AUTOSAR XML (schema 4-3-0)
standard types defined: sint8, sint16, sint32, sint64, uint8, uint16, uint32, uint64, float32, float64, boolean
package /MQBw_Baseline
  system System
    system mapping System_Mappings
      data-mappings:
        communication-direction=IN, data-element=Grundumfang_XIX_eCS.Geltungsbereich_MQBw_Baseline.RP_IF_AB_Crash_Int_XIX_Grundumfang_XIX_eCS.DE_AB_Crash_Int, system-signal=AB_Crash_Int
        communication-direction=IN, data-element=Grundumfang_XIX_eCS.Geltungsbereich_MQBw_Baseline.RP_IF_AB_Gurtschloss_Reihe2_BF_XIX_Grundumfang_XIX_eCS.DE_AB_Gurtschloss_Reihe2_BF, system-signal=AB_Gurtschloss_Reihe2_BF
        communication-direction=IN, data-element=Grundumfang_XIX_eCS.Geltungsbereich_MQBw_Baseline.RP_IF_AB_Gurtschloss_BF_XIX_Grundumfang_XIX_eCS.DE_AB_Gurtschloss_BF, system-signal=AB_Gurtschloss_BF
        communication-direction=IN, data-element=Grundumfang_XIX_eCS.Geltungsbereich_MQBw_Baseline.RP_IF_AB_Gurtschloss_Reihe2_FA_XIX_Grundumfang_XIX_eCS.DE_AB_Gurtschloss_Reihe2_FA, system-signal=AB_Gurtschloss_Reihe2_FA
        communication-direction=IN, data-element=Grundumfang_XIX_eCS.Geltungsbereich_MQBw_Baseline.RP_IF_AB_Gurtschloss_Reihe3_BF_XIX_Grundumfang_XIX_eCS.DE_AB_Gurtschloss_Reihe3_BF, system-signal=AB_Gurtschloss_Reihe3_BF
        communication-direction=IN, data-element=Grundumfang_XIX_eCS.Geltungsbereich_MQBw_Baseline.RP_IF_AB_Gurtschloss_Reihe3_FA_XIX_Grundumfang_XIX_eCS.DE_AB_Gurtschloss_Reihe3_FA, system-signal=AB_Gurtschloss_Reihe3_FA
        communication-direction=IN, data-element=Grundumfang_XIX_eCS.Geltungsbereich_MQBw_Baseline.RP_IF_AB_Gurtschloss_FA_XIX_Grundumfang_XIX_eCS.DE_AB_Gurtschloss_FA, system-signal=AB_Gurtschloss_FA
        communication-direction=OUT, data-element=Grundumfang_XIX_eCS.Geltungsbereich_MQBw_Baseline.SP_IF_eCS_HW_defekt_XIX_Grundumfang_XIX_eCS.DE_eCS_HW_defekt, system-signal=eCS_HW_defekt
        communication-direction=OUT, data-element=Grundumfang_XIX_eCS.Geltungsbereich_MQBw_Baseline.SP_IF_eCS_Gurtschloss_Status_Reihe2_FA_XIX_Grundumfang_XIX_eCS.DE_eCS_Gurtschloss_Status_Reihe2_FA, system-signal=eCS_Gurtschloss_Status_Reihe2_FA
        communication-direction=OUT, data-element=Grundumfang_XIX_eCS.Geltungsbereich_MQBw_Baseline.SP_IF_eCS_SBS_Belegung_Reihe2_BF_XIX_Grundumfang_XIX_eCS.DE_eCS_SBS_Belegung_Reihe2_BF, system-signal=eCS_SBS_Belegung_Reihe2_BF
        communication-direction=OUT, data-element=Grundumfang_XIX_eCS.Geltungsbereich_MQBw_Baseline.SP_IF_eCS_Status_XIX_Grundumfang_XIX_eCS.DE_eCS_Status, system-signal=eCS_Status
        communication-direction=OUT, data-element=Grundumfang_XIX_eCS.Geltungsbereich_MQBw_Baseline.SP_IF_eCS_Gurtschloss_Status_Reihe2_BF_XIX_Grundumfang_XIX_eCS.DE_eCS_Gurtschloss_Status_Reihe2_BF, system-signal=eCS_Gurtschloss_Status_Reihe2_BF
        communication-direction=OUT, data-element=Grundumfang_XIX_eCS.Geltungsbereich_MQBw_Baseline.SP_IF_eCS_SBS_Belegung_Reihe2_FA_XIX_Grundumfang_XIX_eCS.DE_eCS_SBS_Belegung_Reihe2_FA, system-signal=eCS_SBS_Belegung_Reihe2_FA
        communication-direction=OUT, data-element=Grundumfang_XIX_eCS.Geltungsbereich_MQBw_Baseline.SP_IF_eCS_Stoerung_XIX_Grundumfang_XIX_eCS.DE_eCS_Stoerung, system-signal=eCS_Stoerung
        communication-direction=IN, data-element=Grundumfang_XIX_eCS.Geltungsbereich_MQBw_Baseline.RP_IF_AB_eCS_Aktuatortest_FA_XIX_Grundumfang_XIX_eCS.DE_AB_eCS_Aktuatortest_FA, system-signal=AB_eCS_Aktuatortest_FA
        communication-direction=IN, data-element=Grundumfang_XIX_eCS.Geltungsbereich_MQBw_Baseline.RP_IF_AB_eCS_Aktuatortest_Reihe2_BF_XIX_Grundumfang_XIX_eCS.DE_AB_eCS_Aktuatortest_Reihe2_BF, system-signal=AB_eCS_Aktuatortest_Reihe2_BF
        communication-direction=IN, data-element=Grundumfang_XIX_eCS.Geltungsbereich_MQBw_Baseline.RP_IF_AB_eCS_Aktuatortest_BF_XIX_Grundumfang_XIX_eCS.DE_AB_eCS_Aktuatortest_BF, system-signal=AB_eCS_Aktuatortest_BF
        communication-direction=IN, data-element=Grundumfang_XIX_eCS.Geltungsbereich_MQBw_Baseline.RP_IF_AB_eCS_Aktuatortest_Reihe3_BF_XIX_Grundumfang_XIX_eCS.DE_AB_eCS_Aktuatortest_Reihe3_BF, system-signal=AB_eCS_Aktuatortest_Reihe3_BF
        communication-direction=IN, data-element=Grundumfang_XIX_eCS.Geltungsbereich_MQBw_Baseline.RP_IF_AB_eCS_Aktuatortest_Reihe3_FA_XIX_Grundumfang_XIX_eCS.DE_AB_eCS_Aktuatortest_Reihe3_FA, system-signal=AB_eCS_Aktuatortest_Reihe3_FA
        communication-direction=IN, data-element=Grundumfang_XIX_eCS.Geltungsbereich_MQBw_Baseline.RP_IF_AB_eCS_Aktuatortest_Reihe2_FA_XIX_Grundumfang_XIX_eCS.DE_AB_eCS_Aktuatortest_Reihe2_FA, system-signal=AB_eCS_Aktuatortest_Reihe2_FA
      sw-mappings:
        swc to ecu mapping MAPPING_Grundumfang_XIX_eCS: component=Geltungsbereich_MQBw_Baseline.Grundumfang_XIX_eCS, ecu-instance=eCS
    root-software-compositions:
      root sw composition prototype Geltungsbereich_MQBw_Baseline: software-composition=Geltungsbereich_MQBw_Baseline
package /ECU
  ecu instance eCS: associated-com-i-pdu-group=[eCS_XIX_Airbag_SUBCANFD_Tx, eCS_XIX_Airbag_SUBCANFD_Rx], diagnostic-address=16902, sleep-mode-supported=true, wake-up-over-bus-supported=false
    can communication controller CT_Airbag_SUBCANFD: wake-up-by-controller-supported=true, can-controller-attributes=can-controller-configuration-requirements={can-controller-fd-requirements={max-number-of-time-quanta-per-bit=20, max-sample-point=80.0, max-sync-jump-width=20.0, min-number-of-time-quanta-per-bit=20, min-sample-point=80.0, min-sync-jump-width=20.0}, max-number-of-time-quanta-per-bit=20, max-sample-point=80.0, max-sync-jump-width=20.0, min-number-of-time-quanta-per-bit=20, min-sample-point=80.0, min-sync-jump-width=20.0}
    can communication connector CN_Airbag_SUBCANFD: comm-controller=CT_Airbag_SUBCANFD, pnc-gateway-type=NONE
package /Cluster
  can cluster Airbag_SUBCANFD: baudrate=500000, protocol-name=CAN, protocol-version=2.0, bus-off-recovery={bor-counter-l-1-to-l-2=1, bor-time-l-1=0.05, bor-time-l-2=0.2}, can-fd-baudrate=500000  # SubCAN FD Airbag
    can physical channel CHNL: comm-connectors=CN_Airbag_SUBCANFD
      frame Airbag_01_XIX_Airbag_SUBCANFD: id 0x40, to eCS, frame-length=8, can-addressing-mode=STANDARD, can-frame-rx-behavior=CAN-FD, can-frame-tx-behavior=CAN-FD
        pdu Airbag_01_XIX_Airbag_SUBCANFD: length=8, minimum-delay=0.01, transmission-mode-true-timing={cyclic-timing={time-offset=0, time-period=0.04}, event-controlled-timing={number-of-repetitions=5, repetition-period=0.01}}, unused-bit-pattern=0
          signal Airbag_01_CRC_XIX_Airbag_01_XIX_Airbag_SUBCANFD: start 0, 8 bit, little-endian, data-type-policy=OVERRIDE, i-signal-type=PRIMITIVE, base-type=BT_Airbag_01_CRC, compu {phys=raw for raw 0..255}, range phys 0..255, raw 0..255, transfer-property=TRIGGERED-WITHOUT-REPETITION  # Für MLB: "Berechnung siehe Lastenheft "Kommunikationsabsicherung für FlexRay und CAN"" Ab MQB und MLBevo: "Berechnung siehe Lastenheft "End-to-End Kommunikationsabsicherung"" Endwerte siehe Begleitdokument "S-PDU Kennungsfolgen"
          signal Airbag_01_BZ_XIX_Airbag_01_XIX_Airbag_SUBCANFD: start 8, 4 bit, little-endian, data-type-policy=OVERRIDE, i-signal-type=PRIMITIVE, base-type=BT_Airbag_01_BZ, compu {phys=raw for raw 0..15}, range phys 0..15, raw 0..15, transfer-property=TRIGGERED-WITHOUT-REPETITION
          signal AB_RGS_Anst_XIX_Airbag_01_XIX_Airbag_SUBCANFD: start 12, 4 bit, little-endian, data-type-policy=OVERRIDE, i-signal-type=PRIMITIVE, init-value=8, base-type=BT_AB_RGS_Anst, compu {4=Cx4_aktiv_Niveau_1 (CM_AB_RGS_Anst_Cx4_aktiv_Niveau_1), 5=Cx5_aktiv_Niveau_2 (CM_AB_RGS_Anst_Cx5_aktiv_Niveau_2), 8=Cx8_deaktiviert (CM_AB_RGS_Anst_Cx8_deaktiviert), 6=Cx6_aktiv_Niveau_3 (CM_AB_RGS_Anst_Cx6_aktiv_Niveau_3), 7=Cx7_aktiv_Niveau_4 (CM_AB_RGS_Anst_Cx7_aktiv_Niveau_4)}, range raw 4..8, transfer-property=TRIGGERED-WITHOUT-REPETITION  # PreCrash-Ansteuerung reversibler Gurtstraffer (Aktivierung und Kraftniveau) 10xx = deaktiviert
          signal AB_Front_Crash_XIX_Airbag_01_XIX_Airbag_SUBCANFD: start 16, 1 bit, little-endian, data-type-policy=OVERRIDE, i-signal-type=PRIMITIVE, init-value=0, base-type=BT_AB_Front_Crash, compu {1=Cx1_Front_Crash (CM_AB_Front_Crash_Cx1_Front_Crash), 0=Cx0_kein_Front_Crash (CM_AB_Front_Crash_Cx0_kein_Front_Crash)}, range raw 0..1, transfer-property=TRIGGERED-WITHOUT-REPETITION  # Bit wird bei Überschreitung der Gurtstraffer-, US- und RdW-Schwelle gesetzt
          signal AB_Heck_Crash_XIX_Airbag_01_XIX_Airbag_SUBCANFD: start 17, 1 bit, little-endian, data-type-policy=OVERRIDE, i-signal-type=PRIMITIVE, init-value=0, base-type=BT_AB_Heck_Crash, compu {1=Cx1_Heck_Crash (CM_AB_Heck_Crash_Cx1_Heck_Crash), 0=Cx0_kein_Heck_Crash (CM_AB_Heck_Crash_Cx0_kein_Heck_Crash)}, range raw 0..1, transfer-property=TRIGGERED-WITHOUT-REPETITION  # Wird für alle neu anlaufenden Projekte umgesetzt: AB8.4, Audi8/VW8
          signal AB_SF_Crash_XIX_Airbag_01_XIX_Airbag_SUBCANFD: start 18, 1 bit, little-endian, data-type-policy=OVERRIDE, i-signal-type=PRIMITIVE, init-value=0, base-type=BT_AB_SF_Crash, compu {0=Cx0_kein_Seiten_Crash_Fahrer (CM_AB_SF_Crash_Cx0_kein_Seiten_Crash_Fahrer), 1=Cx1_Seiten_Crash_Fahrer (CM_AB_SF_Crash_Cx1_Seiten_Crash_Fahrer)}, range raw 0..1, transfer-property=TRIGGERED-WITHOUT-REPETITION  # Z.Zt. nur in Verbindung mit Crash-Intensität >= 100b (Kraftstoffpumpenabschaltung) verwendet.
          signal AB_SB_Crash_XIX_Airbag_01_XIX_Airbag_SUBCANFD: start 19, 1 bit, little-endian, data-type-policy=OVERRIDE, i-signal-type=PRIMITIVE, init-value=0, base-type=BT_AB_SB_Crash, compu {0=Cx0_kein_Seiten_Crash_Beifahrer (CM_AB_SB_Crash_Cx0_kein_Seiten_Crash_Beifahrer), 1=Cx1_Seiten_Crash_Beifahrer (CM_AB_SB_Crash_Cx1_Seiten_Crash_Beifahrer)}, range raw 0..1, transfer-property=TRIGGERED-WITHOUT-REPETITION  # Z.Zt. nur in Verbindung mit Crash-Intensität >= 100b (Kraftstoffpumpenabschaltung) verwendet.
          signal AB_Rollover_Crash_XIX_Airbag_01_XIX_Airbag_SUBCANFD: start 20, 1 bit, little-endian, data-type-policy=OVERRIDE, i-signal-type=PRIMITIVE, init-value=0, base-type=BT_AB_Rollover_Crash, compu {0=Cx0_kein_Rollover (CM_AB_Rollover_Crash_Cx0_kein_Rollover), 1=Cx1_Rollover (CM_AB_Rollover_Crash_Cx1_Rollover)}, range raw 0..1, transfer-property=TRIGGERED-WITHOUT-REPETITION  # Wird im B6/B7 Cabrio und New Beetle Cabrio bedient.
          signal AB_Crash_Int_XIX_Airbag_01_XIX_Airbag_SUBCANFD: start 21, 3 bit, little-endian, data-type-policy=OVERRIDE, i-signal-type=PRIMITIVE, init-value=0, base-type=BT_AB_Crash_Int, compu {3=Cx3_Crash_Intensitaet_2_nur_D4_C7_Colorado_NF_PAG_Crash_im_MLB_B8 (CM_AB_Crash_Int_Cx3_Crash_Intensitaet_2_nur_D4_C7_Colorado_NF_PAG_Crash_im_MLB_B8) (Crash_Intensitaet_2_(nur_D4_C7_Colorado_NF_PAG__Crash_im_MLB_B8)), 1=Cx1_Crash_Intensitaet_1 (CM_AB_Crash_Int_Cx1_Crash_Intensitaet_1), 5=Cx5_Crash_Intensitaet_3_alt_PAG (CM_AB_Crash_Int_Cx5_Crash_Intensitaet_3_alt_PAG) (Crash_Intensitaet_3_(alt_PAG)), 7=Cx7_Crash_Intensitaet_3 (CM_AB_Crash_Int_Cx7_Crash_Intensitaet_3), 0=Cx0_kein_Crash (CM_AB_Crash_Int_Cx0_kein_Crash), 2=Cx2_Crash_Intensitaet_2_nur_Stellgliedtest_MLB_B8 (CM_AB_Crash_Int_Cx2_Crash_Intensitaet_2_nur_Stellgliedtest_MLB_B8) (Crash_Intensitaet_2_(nur_Stellgliedtest_MLB_B8)), 4=Cx4_Crash_Intensitaet_3_alt_VW_AUDI_Stellgliedtest_MLB_B8 (CM_AB_Crash_Int_Cx4_Crash_Intensitaet_3_alt_VW_AUDI_Stellgliedtest_MLB_B8) (Crash_Intensitaet_3_(alt_VW/AUDI__Stellgliedtest_MLB_B8))}, range raw 0..7, transfer-property=TRIGGERED-WITHOUT-REPETITION, to eCS(timeout 0.5 s)  # Crash_Intensität_1 = fahrzeugabhängige Reaktionen im Crash Crash_Intensität_2 = fahrzeugabhängige Reaktionen im Crash Crash_Intensität_3 = fahrzeugabhängige Reaktionen im Crash Die jeweiligen fahrzeugabhängigen Reaktionen im Crash sind in einem separaten Doors Modul im Airbag-SG beschrieben. Die Information bleibt bei jeder Schwellwert-überschreitung für ~10 s bestehen (Achtung: Energiereserve bei abgetrennter Batterie reicht worstcase nur für 150 ms)
          signal AB_Lampe_XIX_Airbag_01_XIX_Airbag_SUBCANFD: start 24, 1 bit, little-endian, data-type-policy=OVERRIDE, i-signal-type=PRIMITIVE, init-value=1, base-type=BT_AB_Lampe, compu {0=Cx0_Aus (CM_AB_Lampe_Cx0_Aus), 1=Cx1_Ein (CM_AB_Lampe_Cx1_Ein)}, range raw 0..1, transfer-property=TRIGGERED-WITHOUT-REPETITION  # Sicherheitswarnlampe im Kombi wird vom Airbag-SG angesteuert; Zustand der Lampe wird auf dem CAN-Bus ausgegeben (auch Blinkinformation).
          signal AB_Deaktiviert_XIX_Airbag_01_XIX_Airbag_SUBCANFD: start 25, 1 bit, little-endian, data-type-policy=OVERRIDE, i-signal-type=PRIMITIVE, init-value=0, base-type=BT_AB_Deaktiviert, compu {0=Cx0_aktiv (CM_AB_Deaktiviert_Cx0_aktiv), 1=Cx1_deaktiviert (CM_AB_Deaktiviert_Cx1_deaktiviert)}, range raw 0..1, transfer-property=TRIGGERED-WITHOUT-REPETITION  # Airbag oder Gurtstraffer wurden per Anpassung deaktiviert: Aktualisierung erst nach Selbsttest
          signal AB_VB_deaktiviert_XIX_Airbag_01_XIX_Airbag_SUBCANFD: start 26, 1 bit, little-endian, data-type-policy=OVERRIDE, i-signal-type=PRIMITIVE, init-value=1, base-type=BT_AB_VB_deaktiviert, compu {1=Cx1_Beifahrerairbag_deaktiviert (CM_AB_VB_deaktiviert_Cx1_Beifahrerairbag_deaktiviert), 0=Cx0_Beifahrerairbag_aktiv (CM_AB_VB_deaktiviert_Cx0_Beifahrerairbag_aktiv)}, range raw 0..1, transfer-property=TRIGGERED-WITHOUT-REPETITION  # Als Option vorgehalten, Beifahrerairbag wurden per Schlüsselschalter oder Insassenerkennung deaktiviert
          signal AB_Systemfehler_XIX_Airbag_01_XIX_Airbag_SUBCANFD: start 27, 1 bit, little-endian, data-type-policy=OVERRIDE, i-signal-type=PRIMITIVE, init-value=0, base-type=BT_AB_Systemfehler, compu {0=Cx0_kein_Fehler (CM_AB_Systemfehler_Cx0_kein_Fehler), 1=Cx1_Airbag_Systemfehler (CM_AB_Systemfehler_Cx1_Airbag_Systemfehler)}, range raw 0..1, transfer-property=TRIGGERED-WITHOUT-REPETITION  # Systemfehler Ggf. wird Warnlampe dauernd eingeschaltet.
          signal AB_Diagnose_XIX_Airbag_01_XIX_Airbag_SUBCANFD: start 28, 1 bit, little-endian, data-type-policy=OVERRIDE, i-signal-type=PRIMITIVE, init-value=0, base-type=BT_AB_Diagnose, compu {1=Cx1_in_Diagnose (CM_AB_Diagnose_Cx1_in_Diagnose), 0=Cx0_nicht_in_Diagnose (CM_AB_Diagnose_Cx0_nicht_in_Diagnose)}, range raw 0..1, transfer-property=TRIGGERED-WITHOUT-REPETITION  # Airbag in Diagnose
          signal AB_Stellgliedtest_XIX_Airbag_01_XIX_Airbag_SUBCANFD: start 29, 1 bit, little-endian, data-type-policy=OVERRIDE, i-signal-type=PRIMITIVE, init-value=0, base-type=BT_AB_Stellgliedtest, compu {0=Cx0_nicht_im_Stellgliedtest (CM_AB_Stellgliedtest_Cx0_nicht_im_Stellgliedtest), 1=Cx1_Airbag_im_Stellgliedtest (CM_AB_Stellgliedtest_Cx1_Airbag_im_Stellgliedtest)}, range raw 0..1, transfer-property=TRIGGERED-WITHOUT-REPETITION  # Information, ob Airbag im Stellgliedtest ist, um eine Notrufauflösung beim Stellgliedtest zu verhindern
          signal AB_Erh_Auf_VB_XIX_Airbag_01_XIX_Airbag_SUBCANFD: start 30, 2 bit, little-endian, data-type-policy=OVERRIDE, i-signal-type=PRIMITIVE, init-value=0, base-type=BT_AB_Erh_Auf_VB, compu {2=Cx2_Beifahrerairbag_aktiviert (CM_AB_Erh_Auf_VB_Cx2_Beifahrerairbag_aktiviert), 1=Cx1_Beifahrerairbag_deaktiviert (CM_AB_Erh_Auf_VB_Cx1_Beifahrerairbag_deaktiviert), 3=Cx3_nicht_definiert (CM_AB_Erh_Auf_VB_Cx3_nicht_definiert), 0=Cx0_keine_Anzeige (CM_AB_Erh_Auf_VB_Cx0_keine_Anzeige)}, range raw 0..3, transfer-property=TRIGGERED-WITHOUT-REPETITION  # Der Fahrer soll bei einem Statuswechsel des Beifahrerairbags (ausgelöst durch die Beifahrerinsassenerkennung oder den Schlüsselschloßschalter) aufmerksam gemacht werden durch eine Anzeige im Kombi. Nur Audi: gültig für: AB2 (4-Türer AU352), B7, C6, D3
          signal AB_Gurtwarn_VF_XIX_Airbag_01_XIX_Airbag_SUBCANFD: start 32, 1 bit, little-endian, data-type-policy=OVERRIDE, i-signal-type=PRIMITIVE, init-value=0, base-type=BT_AB_Gurtwarn_VF, compu {1=Cx1_Gurtwarnung_ausloesen (CM_AB_Gurtwarn_VF_Cx1_Gurtwarnung_ausloesen), 0=Cx0_keine_Warnung (CM_AB_Gurtwarn_VF_Cx0_keine_Warnung)}, range raw 0..1, transfer-property=TRIGGERED-WITHOUT-REPETITION  # Fahrer hat Gurt nicht gesteckt, Anzeige im Kombi
          signal AB_Gurtwarn_VB_XIX_Airbag_01_XIX_Airbag_SUBCANFD: start 33, 1 bit, little-endian, data-type-policy=OVERRIDE, i-signal-type=PRIMITIVE, init-value=0, base-type=BT_AB_Gurtwarn_VB, compu {1=Cx1_Gurtwarnung_ausloesen (CM_AB_Gurtwarn_VB_Cx1_Gurtwarnung_ausloesen), 0=Cx0_keine_Warnung (CM_AB_Gurtwarn_VB_Cx0_keine_Warnung)}, range raw 0..1, transfer-property=TRIGGERED-WITHOUT-REPETITION  # Beifahrer hat Gurt nicht gesteckt, Anzeige im Kombi
          signal AB_Anzeige_Fussg_XIX_Airbag_01_XIX_Airbag_SUBCANFD: start 34, 2 bit, little-endian, data-type-policy=OVERRIDE, i-signal-type=PRIMITIVE, init-value=0, base-type=BT_AB_Anzeige_Fussg, compu {0=Cx0_keine_FSG_Aktion_ausgeloest (CM_AB_Anzeige_Fussg_Cx0_keine_FSG_Aktion_ausgeloest), 1=Cx1_Motorhaube_offen (CM_AB_Anzeige_Fussg_Cx1_Motorhaube_offen), 2=Cx2_Systemfehler (CM_AB_Anzeige_Fussg_Cx2_Systemfehler)}, range raw 0..2, transfer-property=TRIGGERED-WITHOUT-REPETITION  # Anzeige für ausgelöste Fussgängerschutz-Aktuatorik
          signal AB_Texte_AKS_XIX_Airbag_01_XIX_Airbag_SUBCANFD: start 36, 2 bit, little-endian, data-type-policy=OVERRIDE, i-signal-type=PRIMITIVE, init-value=0, base-type=BT_AB_Texte_AKS, compu {0=Cx0_keine_AKS_Ausloesung (CM_AB_Texte_AKS_Cx0_keine_AKS_Ausloesung), 1=Cx1_AKS_ausgeloest (CM_AB_Texte_AKS_Cx1_AKS_ausgeloest), 2=Cx2_AKS_Systemfehler (CM_AB_Texte_AKS_Cx2_AKS_Systemfehler)}, range raw 0..2, transfer-property=TRIGGERED-WITHOUT-REPETITION  # Textanzeige für pyrotechnische Auslösung der aktiven Kopfstütze (AKS)
          signal AB_PAO_Leuchte_Anf_XIX_Airbag_01_XIX_Airbag_SUBCANFD: start 38, 1 bit, little-endian, data-type-policy=OVERRIDE, i-signal-type=PRIMITIVE, init-value=1, base-type=BT_AB_PAO_Leuchte_Anf, compu {0=Cx0_Leuchte_ausschalten (CM_AB_PAO_Leuchte_Anf_Cx0_Leuchte_ausschalten), 1=Cx1_Leuchte_einschalten (CM_AB_PAO_Leuchte_Anf_Cx1_Leuchte_einschalten)}, range raw 0..1, transfer-property=TRIGGERED-WITHOUT-REPETITION  # Anforderung an die Passenger-Airbag-Off Leuchte in der Dachkonsole (ein / aus), Einsatz nur bei PAG
          signal AB_MKB_gueltig_XIX_Airbag_01_XIX_Airbag_SUBCANFD: start 39, 1 bit, little-endian, data-type-policy=OVERRIDE, i-signal-type=PRIMITIVE, init-value=0, base-type=BT_AB_MKB_gueltig, compu {0=Cx0_Multikollisionsbremsung_nicht_freigeschaltet (CM_AB_MKB_gueltig_Cx0_Multikollisionsbremsung_nicht_freigeschaltet), 1=Cx1_Multikollisionsbremsung_freigeschaltet (CM_AB_MKB_gueltig_Cx1_Multikollisionsbremsung_freigeschaltet)}, range raw 0..1, transfer-property=TRIGGERED-WITHOUT-REPETITION  # Multi-Kollisions-Bremsung im Airbag freigeschaltet
          signal AB_MKB_Anforderung_XIX_Airbag_01_XIX_Airbag_SUBCANFD: start 40, 1 bit, little-endian, data-type-policy=OVERRIDE, i-signal-type=PRIMITIVE, init-value=0, base-type=BT_AB_MKB_Anforderung, compu {0=Cx0_Multikollisionsbremsung_nicht_angefordert (CM_AB_MKB_Anforderung_Cx0_Multikollisionsbremsung_nicht_angefordert), 1=Cx1_Multikollisionsbremsung_angefordert (CM_AB_MKB_Anforderung_Cx1_Multikollisionsbremsung_angefordert)}, range raw 0..1, transfer-property=TRIGGERED-WITHOUT-REPETITION  # Anforderung Multi-Kollisions-Bremsung
          signal AB_Versorgungsspannung_XIX_Airbag_01_XIX_Airbag_SUBCANFD: start 41, 1 bit, little-endian, data-type-policy=OVERRIDE, i-signal-type=PRIMITIVE, init-value=0, base-type=BT_AB_Versorgungsspannung, compu {0=Cx0_plausibel (CM_AB_Versorgungsspannung_Cx0_plausibel), 1=Cx1_unplausibel (CM_AB_Versorgungsspannung_Cx1_unplausibel)}, range raw 0..1, transfer-property=TRIGGERED-WITHOUT-REPETITION  # Übertragung der Plausibilitätsinformation Kl.15-Last vs. Kl.15-CAN. Bedienung im Fall Kl.15-Last "EIN" und Kl.15-CAN "AUS" mit Ausgabe Warnung/Akustik im Kombi.
          signal AB_Deaktivierung_HV_XIX_Airbag_01_XIX_Airbag_SUBCANFD: start 42, 3 bit, little-endian, data-type-policy=OVERRIDE, i-signal-type=PRIMITIVE, init-value=0, base-type=BT_AB_Deaktivierung_HV, invalid-value=Invalid_AB_Deaktivierung_HV_XIX_Airbag_01_XIX_Airbag_SUBCANFD:7, compu {7=Cx7_Fehler (CM_AB_Deaktivierung_HV_Cx7_Fehler), 0=Cx0_keine_Deaktivierung (CM_AB_Deaktivierung_HV_Cx0_keine_Deaktivierung), 1=Cx1_Deaktivierung_1 (CM_AB_Deaktivierung_HV_Cx1_Deaktivierung_1), 2=Cx2_Deaktivierung_2 (CM_AB_Deaktivierung_HV_Cx2_Deaktivierung_2), 3=Cx3_Deaktivierung_3 (CM_AB_Deaktivierung_HV_Cx3_Deaktivierung_3), 4=Cx4_Deaktivierung_4 (CM_AB_Deaktivierung_HV_Cx4_Deaktivierung_4), 5=Cx5_Deaktivierung_5 (CM_AB_Deaktivierung_HV_Cx5_Deaktivierung_5), 6=Cx6_Deaktivierung_6 (CM_AB_Deaktivierung_HV_Cx6_Deaktivierung_6)}, range raw 0..7, transfer-property=TRIGGERED-WITHOUT-REPETITION  # Deaktivierung des HV-Systems und der HV-Teilnehmer im Crash (u.a. Hybrid- und Elektrofahrzeuge)
          signal AB_EDR_Trigger_XIX_Airbag_01_XIX_Airbag_SUBCANFD: start 45, 2 bit, little-endian, data-type-policy=OVERRIDE, i-signal-type=PRIMITIVE, init-value=0, base-type=BT_AB_EDR_Trigger, compu {0=Cx0_No_Event (CM_AB_EDR_Trigger_Cx0_No_Event), 2=Cx2_NonDeployment_Event (CM_AB_EDR_Trigger_Cx2_NonDeployment_Event), 3=Cx3_Deployment_Event (CM_AB_EDR_Trigger_Cx3_Deployment_Event), 1=Cx1_Start_Event (CM_AB_EDR_Trigger_Cx1_Start_Event)}, range raw 0..3, transfer-property=TRIGGERED-WITHOUT-REPETITION  # Triggerbedingung zur dezentralen Aufzeichnung unfallrelevanter Daten im Event Data Recorder
          signal AB_Belegung_VF_XIX_Airbag_01_XIX_Airbag_SUBCANFD: start 47, 2 bit, little-endian, data-type-policy=OVERRIDE, i-signal-type=PRIMITIVE, init-value=0, base-type=BT_AB_Belegung_VF, invalid-value=Invalid_AB_Belegung_VF_XIX_Airbag_01_XIX_Airbag_SUBCANFD:1, compu {1=Cx1_Fehler (CM_AB_Belegung_VF_Cx1_Fehler), 0=Cx0_nicht_verfuegbar (CM_AB_Belegung_VF_Cx0_nicht_verfuegbar), 2=Cx2_nicht_belegt (CM_AB_Belegung_VF_Cx2_nicht_belegt), 3=Cx3_belegt (CM_AB_Belegung_VF_Cx3_belegt)}, range raw 0..3, transfer-property=TRIGGERED-WITHOUT-REPETITION  # Belegungserkennung vorne Fahrer.
          signal AB_Gurtschloss_FA_ext_XIX_Airbag_01_XIX_Airbag_SUBCANFD: start 49, 3 bit, little-endian, data-type-policy=OVERRIDE, i-signal-type=PRIMITIVE, init-value=6, base-type=BT_AB_Gurtschloss_FA_ext, invalid-value=Invalid_AB_Gurtschloss_FA_ext_XIX_Airbag_01_XIX_Airbag_SUBCANFD:7, compu {7=Cx7_Fehler (CM_AB_Gurtschloss_FA_ext_Cx7_Fehler), 2=Cx2_nicht_gesteckt (CM_AB_Gurtschloss_FA_ext_Cx2_nicht_gesteckt), 6=Cx6_Init (CM_AB_Gurtschloss_FA_ext_Cx6_Init), 1=Cx1_reserviert (CM_AB_Gurtschloss_FA_ext_Cx1_reserviert), 3=Cx3_gesteckt (CM_AB_Gurtschloss_FA_ext_Cx3_gesteckt), 4=Cx4_dauerhaft_nicht_gesteckt (CM_AB_Gurtschloss_FA_ext_Cx4_dauerhaft_nicht_gesteckt), 0=Cx0_nicht_verbaut (CM_AB_Gurtschloss_FA_ext_Cx0_nicht_verbaut), 5=Cx5_dauerhaft_gesteckt (CM_AB_Gurtschloss_FA_ext_Cx5_dauerhaft_gesteckt)}, range raw 0..7, transfer-property=TRIGGERED-WITHOUT-REPETITION  # Das Ergebnis der Basisfunktion "Plausibilisierung Gurtschloss" des Verlassenskonzepts wird im Signal dargestellt.
          signal AB_Gurtschloss_FA_ext_aktiv_XIX_Airbag_01_XIX_Airbag_SUBCANFD: start 52, 1 bit, little-endian, data-type-policy=OVERRIDE, i-signal-type=PRIMITIVE, init-value=0, base-type=BT_AB_Gurtschloss_FA_ext_aktiv, compu {1=Cx1_aktiv (CM_AB_Gurtschloss_FA_ext_aktiv_Cx1_aktiv), 0=Cx0_inaktiv (CM_AB_Gurtschloss_FA_ext_aktiv_Cx0_inaktiv)}, range raw 0..1, transfer-property=TRIGGERED-WITHOUT-REPETITION  # Über dieses Signal wird signalisiert ob die Erweiterte Gurtdiagnose (Ergebnis wird im Signal AB_Gurtschloss_FA_ext dargestellt) aktiviert oder deaktiviert ist.
          signal AB_eCS_Error_XIX_Airbag_01_XIX_Airbag_SUBCANFD: start 53, 1 bit, little-endian, data-type-policy=OVERRIDE, i-signal-type=PRIMITIVE, init-value=0, base-type=BT_AB_eCS_Error, compu {0=Cx0_keine_Anzeige (CM_AB_eCS_Error_Cx0_keine_Anzeige), 1=Cx1_Anzeige_anfordern (CM_AB_eCS_Error_Cx1_Anzeige_anfordern)}, range raw 0..1, transfer-property=TRIGGERED-WITHOUT-REPETITION  # Signal zur Anforderung der Anzeige von Störungen im System der elektrischen Gurtverriegelung
          signal ASM_Masterzeit_02_XIX_Airbag_01_XIX_Airbag_SUBCANFD: start 56, 8 bit, little-endian, data-type-policy=OVERRIDE, i-signal-type=PRIMITIVE, init-value=255, base-type=BT_ASM_Masterzeit_02, compu {phys=raw*0.04 for raw 0..254, 255=Cxff_Init (CM_ASM_Masterzeit_02_Cxff_Init); unit Unit_Secon}, range phys 0..10.16 Unit_Secon, raw 0..255, unit=Unit_Secon, transfer-property=TRIGGERED-WITHOUT-REPETITION  # Masterzeit für alle ASM Sender
      frame Airbag_02_XIX_Airbag_SUBCANFD: id 0x520, to eCS, frame-length=8, can-addressing-mode=STANDARD, can-frame-rx-behavior=CAN-FD, can-frame-tx-behavior=CAN-FD
        pdu Airbag_02_XIX_Airbag_SUBCANFD: length=8, minimum-delay=0.02, transmission-mode-true-timing={cyclic-timing={time-offset=0, time-period=0.2}, event-controlled-timing={number-of-repetitions=0, repetition-period=0.0}}, unused-bit-pattern=0
          signal Airbag_02_CRC_XIX_Airbag_02_XIX_Airbag_SUBCANFD: start 0, 8 bit, little-endian, data-type-policy=OVERRIDE, i-signal-type=PRIMITIVE, base-type=BT_Airbag_02_CRC, compu {phys=raw for raw 0..255}, range phys 0..255, raw 0..255, transfer-property=TRIGGERED-WITHOUT-REPETITION  # Für MLB: "Berechnung siehe Lastenheft "Kommunikationsabsicherung für FlexRay und CAN"" Ab MQB und MLBevo: "Berechnung siehe Lastenheft "End-to-End Kommunikationsabsicherung"" Endwerte siehe Begleitdokument "S-PDU Kennungsfolgen"
          signal Airbag_02_BZ_XIX_Airbag_02_XIX_Airbag_SUBCANFD: start 8, 4 bit, little-endian, data-type-policy=OVERRIDE, i-signal-type=PRIMITIVE, base-type=BT_Airbag_02_BZ, compu {phys=raw for raw 0..15}, range phys 0..15, raw 0..15, transfer-property=TRIGGERED-WITHOUT-REPETITION
          signal LoGeWa_Event_Kombiwarnung_XIX_Airbag_02_XIX_Airbag_SUBCANFD: start 12, 4 bit, little-endian, data-type-policy=OVERRIDE, i-signal-type=PRIMITIVE, init-value=0, base-type=BT_LoGeWa_Event_Kombiwarnung, compu {2=Cx2_Traktionsverlust (CM_LoGeWa_Event_Kombiwarnung_Cx2_Traktionsverlust), 4=Cx4_Sichtbehinderung (CM_LoGeWa_Event_Kombiwarnung_Cx4_Sichtbehinderung), 3=Cx3_Panne (CM_LoGeWa_Event_Kombiwarnung_Cx3_Panne), 0=Cx0_Init (CM_LoGeWa_Event_Kombiwarnung_Cx0_Init), 1=Cx1_Unfall (CM_LoGeWa_Event_Kombiwarnung_Cx1_Unfall), 5=Cx5_Aquaplaning (CM_LoGeWa_Event_Kombiwarnung_Cx5_Aquaplaning)}, range raw 0..5, transfer-property=TRIGGERED-WITHOUT-REPETITION  # Event für Kombiwarnung
          signal AB_Anforderung_eCall_XIX_Airbag_02_XIX_Airbag_SUBCANFD: start 16, 1 bit, little-endian, data-type-policy=OVERRIDE, i-signal-type=PRIMITIVE, init-value=0, base-type=BT_AB_Anforderung_eCall, compu {0=Cx0_keine_Anforderung (CM_AB_Anforderung_eCall_Cx0_keine_Anforderung), 1=Cx1_Anforderung (CM_AB_Anforderung_eCall_Cx1_Anforderung)}, range raw 0..1, transfer-property=TRIGGERED-WITHOUT-REPETITION  # Trigger für Car2X Steuergerät das ein eCall Ereignis erkannt wurde.
          signal AB_Anprall_Seite_Beifahrer_XIX_Airbag_02_XIX_Airbag_SUBCANFD: start 17, 1 bit, little-endian, data-type-policy=OVERRIDE, i-signal-type=PRIMITIVE, init-value=0, base-type=BT_AB_Anprall_Seite_Beifahrer, compu {1=Cx1_Anprall_erkannt (CM_AB_Anprall_Seite_Beifahrer_Cx1_Anprall_erkannt), 0=Cx0_kein_Anprall (CM_AB_Anprall_Seite_Beifahrer_Cx0_kein_Anprall)}, range raw 0..1, transfer-property=TRIGGERED-WITHOUT-REPETITION  # Uebermittlung der Lage einer Kollision, Anprallzone Beifahrerseite Seite
          signal AB_Anprall_Rollover_XIX_Airbag_02_XIX_Airbag_SUBCANFD: start 18, 1 bit, little-endian, data-type-policy=OVERRIDE, i-signal-type=PRIMITIVE, init-value=0, base-type=BT_AB_Anprall_Rollover, compu {1=Cx1_Anprall_erkannt (CM_AB_Anprall_Rollover_Cx1_Anprall_erkannt), 0=Cx0_kein_Anprall (CM_AB_Anprall_Rollover_Cx0_kein_Anprall)}, range raw 0..1, transfer-property=TRIGGERED-WITHOUT-REPETITION  # Uebermittlung der Lage einer Kollision, Rollover erkannt
          signal AB_Anprall_FGS_XIX_Airbag_02_XIX_Airbag_SUBCANFD: start 19, 1 bit, little-endian, data-type-policy=OVERRIDE, i-signal-type=PRIMITIVE, init-value=0, base-type=BT_AB_Anprall_FGS, compu {0=Cx0_kein_Anprall (CM_AB_Anprall_FGS_Cx0_kein_Anprall), 1=Cx1_Anprall_erkannt (CM_AB_Anprall_FGS_Cx1_Anprall_erkannt)}, range raw 0..1, transfer-property=TRIGGERED-WITHOUT-REPETITION  # Uebermittlung der Lage einer Kollision, Fussgaengerschutz-Aktorik
          signal AB_Anprall_Front_Beifahrer_XIX_Airbag_02_XIX_Airbag_SUBCANFD: start 20, 1 bit, little-endian, data-type-policy=OVERRIDE, i-signal-type=PRIMITIVE, init-value=0, base-type=BT_AB_Anprall_Front_Beifahrer, compu {0=Cx0_kein_Anprall (CM_AB_Anprall_Front_Beifahrer_Cx0_kein_Anprall), 1=Cx1_Anprall_erkannt (CM_AB_Anprall_Front_Beifahrer_Cx1_Anprall_erkannt)}, range raw 0..1, transfer-property=TRIGGERED-WITHOUT-REPETITION  # Uebermittlung der Lage einer Kollision, Anprallzone Front Beifahrerseite
          signal AB_Anprall_Front_Fahrer_XIX_Airbag_02_XIX_Airbag_SUBCANFD: start 21, 1 bit, little-endian, data-type-policy=OVERRIDE, i-signal-type=PRIMITIVE, init-value=0, base-type=BT_AB_Anprall_Front_Fahrer, compu {1=Cx1_Anprall_erkannt (CM_AB_Anprall_Front_Fahrer_Cx1_Anprall_erkannt), 0=Cx0_kein_Anprall (CM_AB_Anprall_Front_Fahrer_Cx0_kein_Anprall)}, range raw 0..1, transfer-property=TRIGGERED-WITHOUT-REPETITION  # Uebermittlung der Lage einer Kollision, Anprallzone Front Fahrerseite
          signal AB_Anprall_Heck_Beifahrer_XIX_Airbag_02_XIX_Airbag_SUBCANFD: start 22, 1 bit, little-endian, data-type-policy=OVERRIDE, i-signal-type=PRIMITIVE, init-value=0, base-type=BT_AB_Anprall_Heck_Beifahrer, compu {1=Cx1_Anprall_erkannt (CM_AB_Anprall_Heck_Beifahrer_Cx1_Anprall_erkannt), 0=Cx0_kein_Anprall (CM_AB_Anprall_Heck_Beifahrer_Cx0_kein_Anprall)}, range raw 0..1, transfer-property=TRIGGERED-WITHOUT-REPETITION  # Uebermittlung der Lage einer Kollision, Anprallzone Beifahrerseite hinten
          signal AB_Anprall_Heck_Fahrer_XIX_Airbag_02_XIX_Airbag_SUBCANFD: start 23, 1 bit, little-endian, data-type-policy=OVERRIDE, i-signal-type=PRIMITIVE, init-value=0, base-type=BT_AB_Anprall_Heck_Fahrer, compu {1=Cx1_Anprall_erkannt (CM_AB_Anprall_Heck_Fahrer_Cx1_Anprall_erkannt), 0=Cx0_kein_Anprall (CM_AB_Anprall_Heck_Fahrer_Cx0_kein_Anprall)}, range raw 0..1, transfer-property=TRIGGERED-WITHOUT-REPETITION  # Uebermittlung der Lage einer Kollision, Anprallzone Fahrerseite hinten
          signal AB_Wickelklappung_Reihe2_MI_XIX_Airbag_02_XIX_Airbag_SUBCANFD: start 24, 2 bit, little-endian, data-type-policy=OVERRIDE, i-signal-type=PRIMITIVE, init-value=1, base-type=BT_AB_Wickelklappung_Reihe2_MI, compu {2=Cx2_nicht_verriegelt (CM_AB_Wickelklappung_Reihe2_MI_Cx2_nicht_verriegelt), 3=Cx3_verriegelt (CM_AB_Wickelklappung_Reihe2_MI_Cx3_verriegelt), 0=Cx0_nicht_verbaut (CM_AB_Wickelklappung_Reihe2_MI_Cx0_nicht_verbaut), 1=Cx1_nicht_verfuegbar_Fehler_oder_Init (CM_AB_Wickelklappung_Reihe2_MI_Cx1_nicht_verfuegbar_Fehler_oder_Init) (nicht_verfuegbar__Fehler_oder_Init)}, range raw 0..3, transfer-property=TRIGGERED-WITHOUT-REPETITION  # Status Wickelklappung 2. Reihe Mitte, Mehrausstattung
          signal AB_Belegung_VB_XIX_Airbag_02_XIX_Airbag_SUBCANFD: start 26, 2 bit, little-endian, data-type-policy=OVERRIDE, i-signal-type=PRIMITIVE, init-value=0, base-type=BT_AB_Belegung_VB, invalid-value=Invalid_AB_Belegung_VB_XIX_Airbag_02_XIX_Airbag_SUBCANFD:1, compu {1=Cx1_Fehler (CM_AB_Belegung_VB_Cx1_Fehler), 0=Cx0_nicht_verfuegbar (CM_AB_Belegung_VB_Cx0_nicht_verfuegbar), 2=Cx2_nicht_belegt (CM_AB_Belegung_VB_Cx2_nicht_belegt), 3=Cx3_belegt (CM_AB_Belegung_VB_Cx3_belegt)}, range raw 0..3, transfer-property=TRIGGERED-WITHOUT-REPETITION  # Belegungserkennung vorne Beifahrer. Wird in US-Steuergeräten über Bladder-Matte bedient, optional bei RdW, falls SBE_EuroNCAP entschieden wird.
          signal AB_Abschaltanf_SIH_BF_XIX_Airbag_02_XIX_Airbag_SUBCANFD: start 28, 1 bit, little-endian, data-type-policy=OVERRIDE, i-signal-type=PRIMITIVE, init-value=0, base-type=BT_AB_Abschaltanf_SIH_BF, compu {1=Cx1_Abschaltung_angefordert (CM_AB_Abschaltanf_SIH_BF_Cx1_Abschaltung_angefordert), 0=Cx0_Normalbetrieb (CM_AB_Abschaltanf_SIH_BF_Cx0_Normalbetrieb)}, range raw 0..1, transfer-property=TRIGGERED-WITHOUT-REPETITION  # Die Insassenerkennung auf der Beifahrerseite fordert bei Übertemperatur eine Abschaltung der Sitzheizung an. Die Übertemperatur kann bei niederohmigen Nebenschlüssen der Sitzheizungsmatte als Folge von zu hohem resultierenden Strom auftreten.
          signal AB_Anprall_Seite_Fahrer_XIX_Airbag_02_XIX_Airbag_SUBCANFD: start 29, 1 bit, little-endian, data-type-policy=OVERRIDE, i-signal-type=PRIMITIVE, init-value=0, base-type=BT_AB_Anprall_Seite_Fahrer, compu {1=Cx1_Anprall_erkannt (CM_AB_Anprall_Seite_Fahrer_Cx1_Anprall_erkannt), 0=Cx0_kein_Anprall (CM_AB_Anprall_Seite_Fahrer_Cx0_kein_Anprall)}, range raw 0..1, transfer-property=TRIGGERED-WITHOUT-REPETITION  # Uebermittlung der Lage einer Kollision, Anprallzone Fahrerseite Seite
          signal SC_PAO_Schriftzug_Anf_XIX_Airbag_02_XIX_Airbag_SUBCANFD: start 30, 2 bit, little-endian, data-type-policy=OVERRIDE, i-signal-type=PRIMITIVE, init-value=0, base-type=BT_SC_PAO_Schriftzug_Anf, compu {2=Cx2_LED_blinken (CM_SC_PAO_Schriftzug_Anf_Cx2_LED_blinken) (LED blinken), 3=Cx3_reserviert (CM_SC_PAO_Schriftzug_Anf_Cx3_reserviert), 0=Cx0_LED_aus (CM_SC_PAO_Schriftzug_Anf_Cx0_LED_aus) (LED aus), 1=Cx1_LED_an (CM_SC_PAO_Schriftzug_Anf_Cx1_LED_an) (LED an)}, range raw 0..3, transfer-property=TRIGGERED-WITHOUT-REPETITION  # Sollwert für LED "PASSENGER AIRBAG" in Anzeige Passenger Airbag On/Off
          signal SC_PAO_ON_Anf_XIX_Airbag_02_XIX_Airbag_SUBCANFD: start 32, 2 bit, little-endian, data-type-policy=OVERRIDE, i-signal-type=PRIMITIVE, init-value=0, base-type=BT_SC_PAO_ON_Anf, compu {1=Cx1_LED_an (CM_SC_PAO_ON_Anf_Cx1_LED_an) (LED an), 0=Cx0_LED_aus (CM_SC_PAO_ON_Anf_Cx0_LED_aus) (LED aus), 3=Cx3_reserviert (CM_SC_PAO_ON_Anf_Cx3_reserviert), 2=Cx2_LED_blinken (CM_SC_PAO_ON_Anf_Cx2_LED_blinken) (LED blinken)}, range raw 0..3, transfer-property=TRIGGERED-WITHOUT-REPETITION  # Sollwert für LED "ON" in Anzeige Passenger Airbag On/Off
          signal SC_PAO_OFF_Anf_XIX_Airbag_02_XIX_Airbag_SUBCANFD: start 34, 2 bit, little-endian, data-type-policy=OVERRIDE, i-signal-type=PRIMITIVE, init-value=0, base-type=BT_SC_PAO_OFF_Anf, compu {3=Cx3_reserviert (CM_SC_PAO_OFF_Anf_Cx3_reserviert), 1=Cx1_LED_an (CM_SC_PAO_OFF_Anf_Cx1_LED_an) (LED an), 2=Cx2_LED_blinken (CM_SC_PAO_OFF_Anf_Cx2_LED_blinken) (LED blinken), 0=Cx0_LED_aus (CM_SC_PAO_OFF_Anf_Cx0_LED_aus) (LED aus)}, range raw 0..3, transfer-property=TRIGGERED-WITHOUT-REPETITION  # Sollwert für LED "OFF" in Anzeige Passenger Airbag On/Off
          signal AB_Crashschwere_XIX_Airbag_02_XIX_Airbag_SUBCANFD: start 36, 3 bit, little-endian, data-type-policy=OVERRIDE, i-signal-type=PRIMITIVE, init-value=0, base-type=BT_AB_Crashschwere, invalid-value=Invalid_AB_Crashschwere_XIX_Airbag_02_XIX_Airbag_SUBCANFD:7, compu {7=Cx7_Fehler (CM_AB_Crashschwere_Cx7_Fehler), 6=Cx6_Crashschwere_2_bis_5 (CM_AB_Crashschwere_Cx6_Crashschwere_2_bis_5), 3=Cx3_Crashschwere_3 (CM_AB_Crashschwere_Cx3_Crashschwere_3), 4=Cx4_Crashschwere_4 (CM_AB_Crashschwere_Cx4_Crashschwere_4), 0=Cx0_kein_Ereignis (CM_AB_Crashschwere_Cx0_kein_Ereignis), 1=Cx1_Crashschwere_1 (CM_AB_Crashschwere_Cx1_Crashschwere_1), 2=Cx2_Crashschwere_2 (CM_AB_Crashschwere_Cx2_Crashschwere_2), 5=Cx5_Crashschwere_5 (CM_AB_Crashschwere_Cx5_Crashschwere_5)}, range raw 0..7, transfer-property=TRIGGERED-WITHOUT-REPETITION  # Übermittlung der Crashschwere an das Gateway (OBDC)
          signal AB_Anforderung_USM_XIX_Airbag_02_XIX_Airbag_SUBCANFD: start 39, 1 bit, little-endian, data-type-policy=OVERRIDE, i-signal-type=PRIMITIVE, init-value=0, base-type=BT_AB_Anforderung_USM, compu {0=Cx0_keine_Anforderung (CM_AB_Anforderung_USM_Cx0_keine_Anforderung), 1=Cx1_Anforderung (CM_AB_Anforderung_USM_Cx1_Anforderung)}, range raw 0..1, transfer-property=TRIGGERED-WITHOUT-REPETITION  # Trigger für Gateway (OBDC) und MIB/MMI, dass ein USM-Ereignis erkannt wurde.
          signal AB_Gurtschloss_FA_XIX_Airbag_02_XIX_Airbag_SUBCANFD: start 40, 2 bit, little-endian, data-type-policy=OVERRIDE, i-signal-type=PRIMITIVE, init-value=1, base-type=BT_AB_Gurtschloss_FA, compu {3=Cx3_gesteckt (CM_AB_Gurtschloss_FA_Cx3_gesteckt), 2=Cx2_nicht_gesteckt (CM_AB_Gurtschloss_FA_Cx2_nicht_gesteckt), 0=Cx0_nicht_verbaut (CM_AB_Gurtschloss_FA_Cx0_nicht_verbaut), 1=Cx1_nicht_verfuegbar_Fehler_oder_Init (CM_AB_Gurtschloss_FA_Cx1_nicht_verfuegbar_Fehler_oder_Init) (nicht_verfügbar (Fehler oder Init))}, range raw 0..3, transfer-property=TRIGGERED-WITHOUT-REPETITION, to eCS(timeout 2 s)  # Gurtschlosstatatus Fahrerseite
          signal AB_Gurtschloss_BF_XIX_Airbag_02_XIX_Airbag_SUBCANFD: start 42, 2 bit, little-endian, data-type-policy=OVERRIDE, i-signal-type=PRIMITIVE, init-value=1, base-type=BT_AB_Gurtschloss_BF, compu {3=Cx3_gesteckt (CM_AB_Gurtschloss_BF_Cx3_gesteckt), 2=Cx2_nicht_gesteckt (CM_AB_Gurtschloss_BF_Cx2_nicht_gesteckt), 0=Cx0_nicht_verbaut (CM_AB_Gurtschloss_BF_Cx0_nicht_verbaut), 1=Cx1_nicht_verfuegbar_Fehler_oder_Init (CM_AB_Gurtschloss_BF_Cx1_nicht_verfuegbar_Fehler_oder_Init) (nicht_verfügbar (Fehler oder Init))}, range raw 0..3, transfer-property=TRIGGERED-WITHOUT-REPETITION, to eCS(timeout 2 s)  # Gurtschlossstatus Beifahrerseite
          signal AB_Gurtschloss_Reihe2_FA_XIX_Airbag_02_XIX_Airbag_SUBCANFD: start 44, 2 bit, little-endian, data-type-policy=OVERRIDE, i-signal-type=PRIMITIVE, init-value=1, base-type=BT_AB_Gurtschloss_Reihe2_FA, compu {3=Cx3_gesteckt (CM_AB_Gurtschloss_Reihe2_FA_Cx3_gesteckt), 2=Cx2_nicht_gesteckt (CM_AB_Gurtschloss_Reihe2_FA_Cx2_nicht_gesteckt), 0=Cx0_nicht_verbaut (CM_AB_Gurtschloss_Reihe2_FA_Cx0_nicht_verbaut), 1=Cx1_nicht_verfuegbar_Fehler_oder_Init (CM_AB_Gurtschloss_Reihe2_FA_Cx1_nicht_verfuegbar_Fehler_oder_Init) (nicht_verfügbar (Fehler oder Init))}, range raw 0..3, transfer-property=TRIGGERED-WITHOUT-REPETITION, to eCS(timeout 2 s)  # Gurtschlossstatus 2. Reihe Fahrerseite, Mehrausstattung
          signal AB_Gurtschloss_Reihe2_MI_XIX_Airbag_02_XIX_Airbag_SUBCANFD: start 46, 2 bit, little-endian, data-type-policy=OVERRIDE, i-signal-type=PRIMITIVE, init-value=1, base-type=BT_AB_Gurtschloss_Reihe2_MI, compu {3=Cx3_gesteckt (CM_AB_Gurtschloss_Reihe2_MI_Cx3_gesteckt), 2=Cx2_nicht_gesteckt (CM_AB_Gurtschloss_Reihe2_MI_Cx2_nicht_gesteckt), 0=Cx0_nicht_verbaut (CM_AB_Gurtschloss_Reihe2_MI_Cx0_nicht_verbaut), 1=Cx1_nicht_verfuegbar_Fehler_oder_Init (CM_AB_Gurtschloss_Reihe2_MI_Cx1_nicht_verfuegbar_Fehler_oder_Init) (nicht_verfügbar (Fehler oder Init))}, range raw 0..3, transfer-property=TRIGGERED-WITHOUT-REPETITION  # Gurtschlossstatus 2. Reihe Mitte, Mehrausstattung
          signal AB_Gurtschloss_Reihe2_BF_XIX_Airbag_02_XIX_Airbag_SUBCANFD: start 48, 2 bit, little-endian, data-type-policy=OVERRIDE, i-signal-type=PRIMITIVE, init-value=1, base-type=BT_AB_Gurtschloss_Reihe2_BF, compu {3=Cx3_gesteckt (CM_AB_Gurtschloss_Reihe2_BF_Cx3_gesteckt), 2=Cx2_nicht_gesteckt (CM_AB_Gurtschloss_Reihe2_BF_Cx2_nicht_gesteckt), 0=Cx0_nicht_verbaut (CM_AB_Gurtschloss_Reihe2_BF_Cx0_nicht_verbaut), 1=Cx1_nicht_verfuegbar_Fehler_oder_Init (CM_AB_Gurtschloss_Reihe2_BF_Cx1_nicht_verfuegbar_Fehler_oder_Init) (nicht_verfügbar (Fehler oder Init))}, range raw 0..3, transfer-property=TRIGGERED-WITHOUT-REPETITION, to eCS(timeout 2 s)  # Gurtschlossstatus 2. Reihe Beifahrerseite, Mehrausstattung
          signal AB_Gurtschloss_Reihe3_FA_XIX_Airbag_02_XIX_Airbag_SUBCANFD: start 50, 2 bit, little-endian, data-type-policy=OVERRIDE, i-signal-type=PRIMITIVE, init-value=1, base-type=BT_AB_Gurtschloss_Reihe3_FA, compu {3=Cx3_gesteckt (CM_AB_Gurtschloss_Reihe3_FA_Cx3_gesteckt), 2=Cx2_nicht_gesteckt (CM_AB_Gurtschloss_Reihe3_FA_Cx2_nicht_gesteckt), 0=Cx0_nicht_verbaut (CM_AB_Gurtschloss_Reihe3_FA_Cx0_nicht_verbaut), 1=Cx1_nicht_verfuegbar_Fehler_oder_Init (CM_AB_Gurtschloss_Reihe3_FA_Cx1_nicht_verfuegbar_Fehler_oder_Init) (nicht_verfügbar (Fehler oder Init))}, range raw 0..3, transfer-property=TRIGGERED-WITHOUT-REPETITION, to eCS(timeout 2 s)  # Gurtschlossstatus 3. Reihe Fahrerseite, Mehrausstattung
          signal AB_Gurtschloss_Reihe3_MI_XIX_Airbag_02_XIX_Airbag_SUBCANFD: start 52, 2 bit, little-endian, data-type-policy=OVERRIDE, i-signal-type=PRIMITIVE, init-value=1, base-type=BT_AB_Gurtschloss_Reihe3_MI, compu {3=Cx3_gesteckt (CM_AB_Gurtschloss_Reihe3_MI_Cx3_gesteckt), 2=Cx2_nicht_gesteckt (CM_AB_Gurtschloss_Reihe3_MI_Cx2_nicht_gesteckt), 0=Cx0_nicht_verbaut (CM_AB_Gurtschloss_Reihe3_MI_Cx0_nicht_verbaut), 1=Cx1_nicht_verfuegbar_Fehler_oder_Init (CM_AB_Gurtschloss_Reihe3_MI_Cx1_nicht_verfuegbar_Fehler_oder_Init) (nicht_verfügbar (Fehler oder Init))}, range raw 0..3, transfer-property=TRIGGERED-WITHOUT-REPETITION  # Gurtschlossstatus 3. Reihe Mitte, Mehrausstattung
          signal AB_Gurtschloss_Reihe3_BF_XIX_Airbag_02_XIX_Airbag_SUBCANFD: start 54, 2 bit, little-endian, data-type-policy=OVERRIDE, i-signal-type=PRIMITIVE, init-value=1, base-type=BT_AB_Gurtschloss_Reihe3_BF, compu {3=Cx3_gesteckt (CM_AB_Gurtschloss_Reihe3_BF_Cx3_gesteckt), 2=Cx2_nicht_gesteckt (CM_AB_Gurtschloss_Reihe3_BF_Cx2_nicht_gesteckt), 0=Cx0_nicht_verbaut (CM_AB_Gurtschloss_Reihe3_BF_Cx0_nicht_verbaut), 1=Cx1_nicht_verfuegbar_Fehler_oder_Init (CM_AB_Gurtschloss_Reihe3_BF_Cx1_nicht_verfuegbar_Fehler_oder_Init) (nicht_verfügbar (Fehler oder Init))}, range raw 0..3, transfer-property=TRIGGERED-WITHOUT-REPETITION, to eCS(timeout 2 s)  # Gurtschlossstatus 3. Reihe Beifahrerseite, Mehrausstattung
          signal AB_Sitzpos_Sens_FA_XIX_Airbag_02_XIX_Airbag_SUBCANFD: start 56, 2 bit, little-endian, data-type-policy=OVERRIDE, i-signal-type=PRIMITIVE, init-value=0, base-type=BT_AB_Sitzpos_Sens_FA, invalid-value=Invalid_AB_Sitzpos_Sens_FA_XIX_Airbag_02_XIX_Airbag_SUBCANFD:1, compu {1=Cx1_Fehler (CM_AB_Sitzpos_Sens_FA_Cx1_Fehler), 3=Cx3_Sitz_vorne (CM_AB_Sitzpos_Sens_FA_Cx3_Sitz_vorne) (Sitz vorne), 2=Cx2_Sitz_nicht_vorne (CM_AB_Sitzpos_Sens_FA_Cx2_Sitz_nicht_vorne) (Sitz nicht vorne), 0=Cx0_nicht_verfuegbar (CM_AB_Sitzpos_Sens_FA_Cx0_nicht_verfuegbar) (nicht verfügbar)}, range raw 0..3, transfer-property=TRIGGERED-WITHOUT-REPETITION  # Ausgabe Sitzposition Fahrer
          signal AB_Sitzpos_Sens_BF_XIX_Airbag_02_XIX_Airbag_SUBCANFD: start 58, 2 bit, little-endian, data-type-policy=OVERRIDE, i-signal-type=PRIMITIVE, init-value=0, base-type=BT_AB_Sitzpos_Sens_BF, invalid-value=Invalid_AB_Sitzpos_Sens_BF_XIX_Airbag_02_XIX_Airbag_SUBCANFD:1, compu {1=Cx1_Fehler (CM_AB_Sitzpos_Sens_BF_Cx1_Fehler), 3=Cx3_Sitz_vorne (CM_AB_Sitzpos_Sens_BF_Cx3_Sitz_vorne) (Sitz vorne), 2=Cx2_Sitz_nicht_vorne (CM_AB_Sitzpos_Sens_BF_Cx2_Sitz_nicht_vorne) (Sitz nicht vorne), 0=Cx0_nicht_verfuegbar (CM_AB_Sitzpos_Sens_BF_Cx0_nicht_verfuegbar) (nicht verfügbar)}, range raw 0..3, transfer-property=TRIGGERED-WITHOUT-REPETITION  # Ausgabe Sitzposition Beifahrer
          signal AB_Wickelklappung_Reihe2_BF_XIX_Airbag_02_XIX_Airbag_SUBCANFD: start 60, 2 bit, little-endian, data-type-policy=OVERRIDE, i-signal-type=PRIMITIVE, init-value=1, base-type=BT_AB_Wickelklappung_Reihe2_BF, compu {2=Cx2_nicht_verriegelt (CM_AB_Wickelklappung_Reihe2_BF_Cx2_nicht_verriegelt), 3=Cx3_verriegelt (CM_AB_Wickelklappung_Reihe2_BF_Cx3_verriegelt), 1=Cx1_nicht_verfuegbar_Fehler_oder_Init (CM_AB_Wickelklappung_Reihe2_BF_Cx1_nicht_verfuegbar_Fehler_oder_Init) (nicht_verfuegbar__Fehler_oder_Init), 0=Cx0_nicht_verbaut (CM_AB_Wickelklappung_Reihe2_BF_Cx0_nicht_verbaut)}, range raw 0..3, transfer-property=TRIGGERED-WITHOUT-REPETITION  # Status Wickelklappung 2. Reihe Beifahrerseite, Mehrausstattung
          signal AB_Wickelklappung_Reihe2_FA_XIX_Airbag_02_XIX_Airbag_SUBCANFD: start 62, 2 bit, little-endian, data-type-policy=OVERRIDE, i-signal-type=PRIMITIVE, init-value=1, base-type=BT_AB_Wickelklappung_Reihe2_FA, compu {1=Cx1_nicht_verfuegbar_Fehler_oder_Init (CM_AB_Wickelklappung_Reihe2_FA_Cx1_nicht_verfuegbar_Fehler_oder_Init) (nicht_verfuegbar__Fehler_oder_Init), 2=Cx2_nicht_verriegelt (CM_AB_Wickelklappung_Reihe2_FA_Cx2_nicht_verriegelt), 0=Cx0_nicht_verbaut (CM_AB_Wickelklappung_Reihe2_FA_Cx0_nicht_verbaut), 3=Cx3_verriegelt (CM_AB_Wickelklappung_Reihe2_FA_Cx3_verriegelt)}, range raw 0..3, transfer-property=TRIGGERED-WITHOUT-REPETITION  # Status Wickelklappung 2. Reihe Fahrerseite, Mehrausstattung
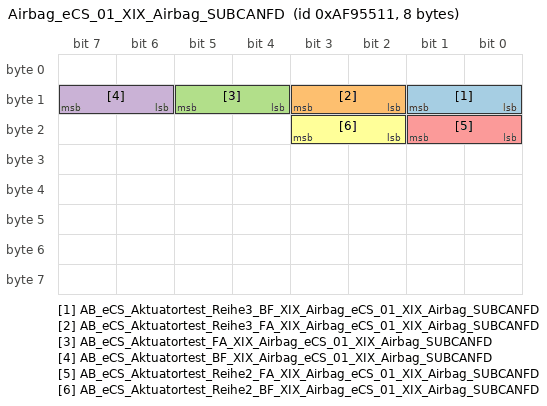
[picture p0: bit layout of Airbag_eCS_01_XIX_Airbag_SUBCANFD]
      frame Airbag_eCS_01_XIX_Airbag_SUBCANFD: id 0xAF95511, to eCS, frame-length=8, can-addressing-mode=EXTENDED, can-frame-rx-behavior=CAN-FD, can-frame-tx-behavior=CAN-FD
        pdu Airbag_eCS_01_XIX_Airbag_SUBCANFD: length=8, transmission-mode-true-timing=cyclic-timing={time-offset=0, time-period=0.05}, unused-bit-pattern=0
          signal AB_eCS_Aktuatortest_Reihe3_BF_XIX_Airbag_eCS_01_XIX_Airbag_SUBCANFD: start 8, 2 bit, little-endian, data-type-policy=OVERRIDE, i-signal-type=PRIMITIVE, init-value=0, base-type=BT_AB_eCS_Aktuatortest_Reihe3_BF, compu {1=Cx1_Verriegelt (CM_AB_eCS_Aktuatortest_Reihe3_BF_Cx1_Verriegelt), 0=Cx0_Keine_Aktion (CM_AB_eCS_Aktuatortest_Reihe3_BF_Cx0_Keine_Aktion), 3=Cx3_Unplausibel (CM_AB_eCS_Aktuatortest_Reihe3_BF_Cx3_Unplausibel), 2=Cx2_Entriegelt (CM_AB_eCS_Aktuatortest_Reihe3_BF_Cx2_Entriegelt)}, range raw 0..3, transfer-property=PENDING, to eCS(timeout 0.5 s)  # Signal zum Stellgliedtest Sitz hinten in 3. SR Beifahrerseite
          signal AB_eCS_Aktuatortest_Reihe3_FA_XIX_Airbag_eCS_01_XIX_Airbag_SUBCANFD: start 10, 2 bit, little-endian, data-type-policy=OVERRIDE, i-signal-type=PRIMITIVE, init-value=0, base-type=BT_AB_eCS_Aktuatortest_Reihe3_FA, compu {2=Cx2_Entriegelt (CM_AB_eCS_Aktuatortest_Reihe3_FA_Cx2_Entriegelt), 0=Cx0_Keine_Aktion (CM_AB_eCS_Aktuatortest_Reihe3_FA_Cx0_Keine_Aktion), 1=Cx1_Verriegelt (CM_AB_eCS_Aktuatortest_Reihe3_FA_Cx1_Verriegelt), 3=Cx3_Unplausibel (CM_AB_eCS_Aktuatortest_Reihe3_FA_Cx3_Unplausibel)}, range raw 0..3, transfer-property=PENDING, to eCS(timeout 0.5 s)  # Signal zum Stellgliedtest Sitz hinten in 3. SR Fahrerseite
          signal AB_eCS_Aktuatortest_FA_XIX_Airbag_eCS_01_XIX_Airbag_SUBCANFD: start 12, 2 bit, little-endian, data-type-policy=OVERRIDE, i-signal-type=PRIMITIVE, init-value=0, base-type=BT_AB_eCS_Aktuatortest_FA, compu {2=Cx2_Entriegelt (CM_AB_eCS_Aktuatortest_FA_Cx2_Entriegelt), 3=Cx3_Unplausibel (CM_AB_eCS_Aktuatortest_FA_Cx3_Unplausibel), 0=Cx0_Keine_Aktion (CM_AB_eCS_Aktuatortest_FA_Cx0_Keine_Aktion), 1=Cx1_Verriegelt (CM_AB_eCS_Aktuatortest_FA_Cx1_Verriegelt)}, range raw 0..3, transfer-property=PENDING, to eCS(timeout 0.5 s)  # Signal zum Stellgliedtest Fahrersitz
          signal AB_eCS_Aktuatortest_BF_XIX_Airbag_eCS_01_XIX_Airbag_SUBCANFD: start 14, 2 bit, little-endian, data-type-policy=OVERRIDE, i-signal-type=PRIMITIVE, init-value=0, base-type=BT_AB_eCS_Aktuatortest_BF, compu {1=Cx1_Verriegelt (CM_AB_eCS_Aktuatortest_BF_Cx1_Verriegelt), 2=Cx2_Entriegelt (CM_AB_eCS_Aktuatortest_BF_Cx2_Entriegelt), 0=Cx0_Keine_Aktion (CM_AB_eCS_Aktuatortest_BF_Cx0_Keine_Aktion), 3=Cx3_Unplausibel (CM_AB_eCS_Aktuatortest_BF_Cx3_Unplausibel)}, range raw 0..3, transfer-property=PENDING, to eCS(timeout 0.5 s)  # Signal zum Stellgliedtest Beifahrersitz
          signal AB_eCS_Aktuatortest_Reihe2_FA_XIX_Airbag_eCS_01_XIX_Airbag_SUBCANFD: start 16, 2 bit, little-endian, data-type-policy=OVERRIDE, i-signal-type=PRIMITIVE, init-value=0, base-type=BT_AB_eCS_Aktuatortest_Reihe2_FA, compu {0=Cx0_Keine_Aktion (CM_AB_eCS_Aktuatortest_Reihe2_FA_Cx0_Keine_Aktion), 1=Cx1_Verriegelt (CM_AB_eCS_Aktuatortest_Reihe2_FA_Cx1_Verriegelt), 2=Cx2_Entriegelt (CM_AB_eCS_Aktuatortest_Reihe2_FA_Cx2_Entriegelt), 3=Cx3_Unplausibel (CM_AB_eCS_Aktuatortest_Reihe2_FA_Cx3_Unplausibel)}, range raw 0..3, transfer-property=PENDING, to eCS(timeout 0.5 s)  # Signal zum Stellgliedtest Sitz hinten in 2. SR Fahrerseite
          signal AB_eCS_Aktuatortest_Reihe2_BF_XIX_Airbag_eCS_01_XIX_Airbag_SUBCANFD: start 18, 2 bit, little-endian, data-type-policy=OVERRIDE, i-signal-type=PRIMITIVE, init-value=0, base-type=BT_AB_eCS_Aktuatortest_Reihe2_BF, compu {1=Cx1_Verriegelt (CM_AB_eCS_Aktuatortest_Reihe2_BF_Cx1_Verriegelt), 3=Cx3_Unplausibel (CM_AB_eCS_Aktuatortest_Reihe2_BF_Cx3_Unplausibel), 0=Cx0_Keine_Aktion (CM_AB_eCS_Aktuatortest_Reihe2_BF_Cx0_Keine_Aktion), 2=Cx2_Entriegelt (CM_AB_eCS_Aktuatortest_Reihe2_BF_Cx2_Entriegelt)}, range raw 0..3, transfer-property=PENDING, to eCS(timeout 0.5 s)  # Signal zum Stellgliedtest Sitz hinten in 2. SR Beifahrerseite
      frame DIA_eCS_Req_XIX_Airbag_SUBCANFD: id 0x17FC4206, to eCS, frame-length=8, can-addressing-mode=EXTENDED, can-frame-rx-behavior=CAN-FD, can-frame-tx-behavior=CAN-FD
        n pdu DIA_eCS_Req_XIX_Airbag_SUBCANFD: length=8
      frame DIA_eCS_Req_FD_XIX_Airbag_SUBCANFD: id 0x1C404206, to eCS, frame-length=64, can-addressing-mode=EXTENDED, can-frame-rx-behavior=CAN-FD, can-frame-tx-behavior=CAN-FD
        n pdu DIA_eCS_Req_FD_XIX_Airbag_SUBCANFD: length=64
      frame DIA_eCS_Resp_XIX_Airbag_SUBCANFD: id 0x17FE4206, from eCS, frame-length=8, can-addressing-mode=EXTENDED, can-frame-rx-behavior=CAN-FD, can-frame-tx-behavior=CAN-FD
        n pdu DIA_eCS_Resp_XIX_Airbag_SUBCANFD: length=8
      frame DIA_eCS_Resp_FD_XIX_Airbag_SUBCANFD: id 0x1C424206, from eCS, frame-length=64, can-addressing-mode=EXTENDED, can-frame-rx-behavior=CAN-FD, can-frame-tx-behavior=CAN-FD
        n pdu DIA_eCS_Resp_FD_XIX_Airbag_SUBCANFD: length=64
      frame Diag_eCS_Req_FD_XIX_Airbag_SUBCANFD: id 0x1C405206, to eCS, frame-length=64, can-addressing-mode=EXTENDED, can-frame-rx-behavior=CAN-FD, can-frame-tx-behavior=CAN-FD
        n pdu Diag_eCS_Req_FD_XIX_Airbag_SUBCANFD: length=64
      frame Diag_eCS_Resp_FD_XIX_Airbag_SUBCANFD: id 0x1C425206, from eCS, frame-length=64, can-addressing-mode=EXTENDED, can-frame-rx-behavior=CAN-FD, can-frame-tx-behavior=CAN-FD
        n pdu Diag_eCS_Resp_FD_XIX_Airbag_SUBCANFD: length=64
      frame OBDC_SSN_eCS_Req_FD_XIX_Airbag_SUBCANFD: id 0x1C407206, to eCS, frame-length=64, can-addressing-mode=EXTENDED, can-frame-rx-behavior=CAN-FD, can-frame-tx-behavior=CAN-FD
        n pdu OBDC_SSN_eCS_Req_FD_XIX_Airbag_SUBCANFD: length=64
      frame OBDC_SSN_eCS_Resp_FD_XIX_Airbag_SUBCANFD: id 0x1C427206, from eCS, frame-length=64, can-addressing-mode=EXTENDED, can-frame-rx-behavior=CAN-FD, can-frame-tx-behavior=CAN-FD
        n pdu OBDC_SSN_eCS_Resp_FD_XIX_Airbag_SUBCANFD: length=64
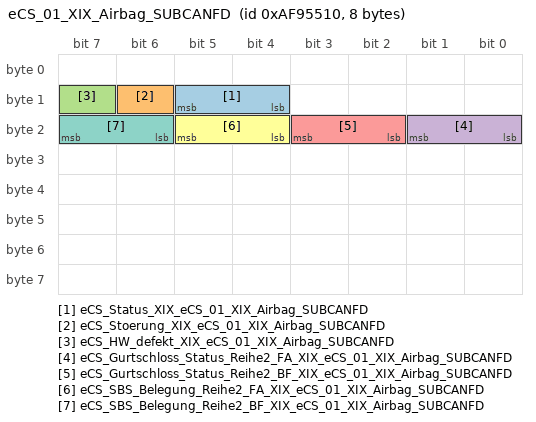
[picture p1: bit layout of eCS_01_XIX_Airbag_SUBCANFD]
      frame eCS_01_XIX_Airbag_SUBCANFD: id 0xAF95510, from eCS, frame-length=8, can-addressing-mode=EXTENDED, can-frame-rx-behavior=CAN-FD, can-frame-tx-behavior=CAN-FD
        pdu eCS_01_XIX_Airbag_SUBCANFD: length=8, transmission-mode-true-timing=cyclic-timing={time-offset=0, time-period=0.05}, unused-bit-pattern=0
          signal eCS_Status_XIX_eCS_01_XIX_Airbag_SUBCANFD: start 12, 2 bit, little-endian, data-type-policy=OVERRIDE, i-signal-type=PRIMITIVE, init-value=0, base-type=BT_eCS_Status, invalid-value=Invalid_eCS_Status_XIX_eCS_01_XIX_Airbag_SUBCANFD:3, compu {3=Cx3_Fehler (CM_eCS_Status_Cx3_Fehler), 0=Cx0_Init (CM_eCS_Status_Cx0_Init), 2=Cx2_entriegelt (CM_eCS_Status_Cx2_entriegelt), 1=Cx1_verriegelt (CM_eCS_Status_Cx1_verriegelt)}, range raw 0..3, transfer-property=PENDING  # Das eCS SG sendet den Status des Gurtband verriegelt oder entriegelt (Magnethub am Gurt gesperrt oder entsperrt)
          signal eCS_Stoerung_XIX_eCS_01_XIX_Airbag_SUBCANFD: start 14, 1 bit, little-endian, data-type-policy=OVERRIDE, i-signal-type=PRIMITIVE, init-value=0, base-type=BT_eCS_Stoerung, compu {0=Cx0_keine_Stoerung (CM_eCS_Stoerung_Cx0_keine_Stoerung), 1=Cx1_Stoerung (CM_eCS_Stoerung_Cx1_Stoerung)}, range raw 0..1, transfer-property=PENDING  # Das eCS signalisiert einen sporadischen Fehler oder einen Kommunikations-Timeout
          signal eCS_HW_defekt_XIX_eCS_01_XIX_Airbag_SUBCANFD: start 15, 1 bit, little-endian, data-type-policy=OVERRIDE, i-signal-type=PRIMITIVE, init-value=0, base-type=BT_eCS_HW_defekt, compu {0=Cx0_nicht_defekt (CM_eCS_HW_defekt_Cx0_nicht_defekt), 1=Cx1_Defekt (CM_eCS_HW_defekt_Cx1_Defekt)}, range raw 0..1, transfer-property=PENDING  # das eCS signalisiert ein HW_defekt
          signal eCS_Gurtschloss_Status_Reihe2_FA_XIX_eCS_01_XIX_Airbag_SUBCANFD: start 16, 2 bit, little-endian, data-type-policy=OVERRIDE, i-signal-type=PRIMITIVE, init-value=1, base-type=BT_eCS_Gurtschloss_Status_Reihe2_FA, compu {2=Cx2_nicht_gesteckt (CM_eCS_Gurtschloss_Status_Reihe2_FA_Cx2_nicht_gesteckt), 3=Cx3_gesteckt (CM_eCS_Gurtschloss_Status_Reihe2_FA_Cx3_gesteckt), 1=Cx1_nicht_verfuegbar_Fehler_o_Init (CM_eCS_Gurtschloss_Status_Reihe2_FA_Cx1_nicht_verfuegbar_Fehler_o_Init), 0=Cx0_nicht_verbaut (CM_eCS_Gurtschloss_Status_Reihe2_FA_Cx0_nicht_verbaut)}, range raw 0..3, transfer-property=PENDING  # Das eCS SG sendet den Status des Gutschlosses 2.SR Fahrer an das Airbag SG
          signal eCS_Gurtschloss_Status_Reihe2_BF_XIX_eCS_01_XIX_Airbag_SUBCANFD: start 18, 2 bit, little-endian, data-type-policy=OVERRIDE, i-signal-type=PRIMITIVE, init-value=1, base-type=BT_eCS_Gurtschloss_Status_Reihe2_BF, compu {2=Cx2_nicht_gesteckt (CM_eCS_Gurtschloss_Status_Reihe2_BF_Cx2_nicht_gesteckt), 1=Cx1_nicht_verfuegbar_Fehler_o_Init (CM_eCS_Gurtschloss_Status_Reihe2_BF_Cx1_nicht_verfuegbar_Fehler_o_Init), 3=Cx3_gesteckt (CM_eCS_Gurtschloss_Status_Reihe2_BF_Cx3_gesteckt), 0=Cx0_nicht_verbaut (CM_eCS_Gurtschloss_Status_Reihe2_BF_Cx0_nicht_verbaut)}, range raw 0..3, transfer-property=PENDING  # Das eCS SG sendet den Status des Gutschlosses 2.SR Beifahrer an das Airbag SG
          signal eCS_SBS_Belegung_Reihe2_FA_XIX_eCS_01_XIX_Airbag_SUBCANFD: start 20, 2 bit, little-endian, data-type-policy=OVERRIDE, i-signal-type=PRIMITIVE, init-value=2, base-type=BT_eCS_SBS_Belegung_Reihe2_FA, compu {1=Cx1_Kurzschluss_nach_Masse (CM_eCS_SBS_Belegung_Reihe2_FA_Cx1_Kurzschluss_nach_Masse), 3=Cx3_belegt (CM_eCS_SBS_Belegung_Reihe2_FA_Cx3_belegt), 2=Cx2_nicht_belegt (CM_eCS_SBS_Belegung_Reihe2_FA_Cx2_nicht_belegt), 0=Cx0_nicht_verfuegbar (CM_eCS_SBS_Belegung_Reihe2_FA_Cx0_nicht_verfuegbar)}, range raw 0..3, transfer-property=PENDING  # Das eCS SG sendet den Status der Sitzbelegung 2.SR Fahrer an dem Airbag SG
          signal eCS_SBS_Belegung_Reihe2_BF_XIX_eCS_01_XIX_Airbag_SUBCANFD: start 22, 2 bit, little-endian, data-type-policy=OVERRIDE, i-signal-type=PRIMITIVE, init-value=2, base-type=BT_eCS_SBS_Belegung_Reihe2_BF, compu {3=Cx3_belegt (CM_eCS_SBS_Belegung_Reihe2_BF_Cx3_belegt), 2=Cx2_nicht_belegt (CM_eCS_SBS_Belegung_Reihe2_BF_Cx2_nicht_belegt), 1=Cx1_Kurzschluss_nach_Masse (CM_eCS_SBS_Belegung_Reihe2_BF_Cx1_Kurzschluss_nach_Masse), 0=Cx0_nicht_verfuegbar (CM_eCS_SBS_Belegung_Reihe2_BF_Cx0_nicht_verfuegbar)}, range raw 0..3, transfer-property=PENDING  # Das eCS SG sendet den Status der Sitzbelegung 2.SR Beifahrer an dem Airbag SG
      pdu triggering PT_Airbag_SUBCANFD_XIX_TPCHType_CANFD_Flash_DIA_XIX_0x1C404206_XIX_0x1C424206_XIX_Physical: pdu=DCM_Airbag_SUBCANFD_XIX_TPCHType_CANFD_Flash_DIA_XIX_0x1C404206_XIX_0x1C424206_XIX_Physical, to eCS
      pdu triggering PT_Airbag_SUBCANFD_XIX_TPCHType_CANFD_Flash_DIA_XIX_0x1C424206_XIX_0x1C404206_XIX_Physical: pdu=DCM_Airbag_SUBCANFD_XIX_TPCHType_CANFD_Flash_DIA_XIX_0x1C424206_XIX_0x1C404206_XIX_Physical, from eCS
      pdu triggering PT_Airbag_SUBCANFD_XIX_TPCHType_CANFD_Diag_XIX_0x1C405206_XIX_0x1C425206_XIX_Physical: pdu=DCM_Airbag_SUBCANFD_XIX_TPCHType_CANFD_Diag_XIX_0x1C405206_XIX_0x1C425206_XIX_Physical, to eCS
      pdu triggering PT_Airbag_SUBCANFD_XIX_TPCHType_CANFD_Diag_XIX_0x1C425206_XIX_0x1C405206_XIX_Physical: pdu=DCM_Airbag_SUBCANFD_XIX_TPCHType_CANFD_Diag_XIX_0x1C425206_XIX_0x1C405206_XIX_Physical, from eCS
      pdu triggering PT_Airbag_SUBCANFD_XIX_TPCHType_CANFD_OBDC_SSN_Diagnose_XIX_0x1C407206_XIX_0x1C427206_XIX_Physical: pdu=DCM_Airbag_SUBCANFD_XIX_TPCHType_CANFD_OBDC_SSN_Diagnose_XIX_0x1C407206_XIX_0x1C427206_XIX_Physical, to eCS
      pdu triggering PT_Airbag_SUBCANFD_XIX_TPCHType_CANFD_OBDC_SSN_Diagnose_XIX_0x1C427206_XIX_0x1C407206_XIX_Physical: pdu=DCM_Airbag_SUBCANFD_XIX_TPCHType_CANFD_OBDC_SSN_Diagnose_XIX_0x1C427206_XIX_0x1C407206_XIX_Physical, from eCS
      pdu triggering PT_Airbag_SUBCANFD_XIX_TPCHType_CANHS_Flash_DIA_XIX_0x17FC4206_XIX_0x17FE4206_XIX_Physical: pdu=DCM_Airbag_SUBCANFD_XIX_TPCHType_CANHS_Flash_DIA_XIX_0x17FC4206_XIX_0x17FE4206_XIX_Physical, to eCS
      pdu triggering PT_Airbag_SUBCANFD_XIX_TPCHType_CANHS_Flash_DIA_XIX_0x17FE4206_XIX_0x17FC4206_XIX_Physical: pdu=DCM_Airbag_SUBCANFD_XIX_TPCHType_CANHS_Flash_DIA_XIX_0x17FE4206_XIX_0x17FC4206_XIX_Physical, from eCS
package /PDU
  dcm i pdu DCM_Airbag_SUBCANFD_XIX_TPCHType_CANFD_Diag_XIX_0x1C405206_XIX_0x1C425206_XIX_Physical: length=512, diag-pdu-type=DIAG-REQUEST
  dcm i pdu DCM_Airbag_SUBCANFD_XIX_TPCHType_CANFD_Diag_XIX_0x1C425206_XIX_0x1C405206_XIX_Physical: length=512, diag-pdu-type=DIAG-RESPONSE
  dcm i pdu DCM_Airbag_SUBCANFD_XIX_TPCHType_CANFD_Flash_DIA_XIX_0x1C404206_XIX_0x1C424206_XIX_Physical: length=512, diag-pdu-type=DIAG-REQUEST
  dcm i pdu DCM_Airbag_SUBCANFD_XIX_TPCHType_CANFD_Flash_DIA_XIX_0x1C424206_XIX_0x1C404206_XIX_Physical: length=512, diag-pdu-type=DIAG-RESPONSE
  dcm i pdu DCM_Airbag_SUBCANFD_XIX_TPCHType_CANFD_OBDC_SSN_Diagnose_XIX_0x1C407206_XIX_0x1C427206_XIX_Physical: length=512, diag-pdu-type=DIAG-REQUEST
  dcm i pdu DCM_Airbag_SUBCANFD_XIX_TPCHType_CANFD_OBDC_SSN_Diagnose_XIX_0x1C427206_XIX_0x1C407206_XIX_Physical: length=512, diag-pdu-type=DIAG-RESPONSE
  dcm i pdu DCM_Airbag_SUBCANFD_XIX_TPCHType_CANHS_Flash_DIA_XIX_0x17FC4206_XIX_0x17FE4206_XIX_Physical: length=512, diag-pdu-type=DIAG-REQUEST
  dcm i pdu DCM_Airbag_SUBCANFD_XIX_TPCHType_CANHS_Flash_DIA_XIX_0x17FE4206_XIX_0x17FC4206_XIX_Physical: length=512, diag-pdu-type=DIAG-RESPONSE
package /IPDUGroup
  i signal i pdu group eCS_XIX_Airbag_SUBCANFD_Rx: communication-direction=IN, communication-mode=CAN_Receive_All, i-signal-i-pdus=[Airbag_02_XIX_Airbag_SUBCANFD, Airbag_01_XIX_Airbag_SUBCANFD, Airbag_eCS_01_XIX_Airbag_SUBCANFD]
  i signal i pdu group eCS_XIX_Airbag_SUBCANFD_Tx: communication-direction=OUT, communication-mode=CAN_Transmit_All, i-signal-i-pdus=eCS_01_XIX_Airbag_SUBCANFD
package /BaseType
  77 x base type, all with category=FIXED_LENGTH, base-type-encoding=NONE:
    BT_AB_Abschaltanf_SIH_BF
    BT_AB_Anforderung_eCall
    BT_AB_Anforderung_USM
    BT_AB_Anprall_FGS
    BT_AB_Anprall_Front_Beifahrer
    BT_AB_Anprall_Front_Fahrer
    BT_AB_Anprall_Heck_Beifahrer
    BT_AB_Anprall_Heck_Fahrer
    BT_AB_Anprall_Rollover
    BT_AB_Anprall_Seite_Beifahrer
    BT_AB_Anprall_Seite_Fahrer
    BT_AB_Anzeige_Fussg
    BT_AB_Belegung_VB
    BT_AB_Belegung_VF
    BT_AB_Crash_Int
    BT_AB_Crashschwere
    BT_AB_Deaktiviert
    BT_AB_Deaktivierung_HV
    BT_AB_Diagnose
    BT_AB_eCS_Aktuatortest_BF
    BT_AB_eCS_Aktuatortest_FA
    BT_AB_eCS_Aktuatortest_Reihe2_BF
    BT_AB_eCS_Aktuatortest_Reihe2_FA
    BT_AB_eCS_Aktuatortest_Reihe3_BF
    BT_AB_eCS_Aktuatortest_Reihe3_FA
    BT_AB_eCS_Error
    BT_AB_EDR_Trigger
    BT_AB_Erh_Auf_VB
    BT_AB_Front_Crash
    BT_AB_Gurtschloss_BF
    BT_AB_Gurtschloss_FA
    BT_AB_Gurtschloss_FA_ext
    BT_AB_Gurtschloss_FA_ext_aktiv
    BT_AB_Gurtschloss_Reihe2_BF
    BT_AB_Gurtschloss_Reihe2_FA
    BT_AB_Gurtschloss_Reihe2_MI
    BT_AB_Gurtschloss_Reihe3_BF
    BT_AB_Gurtschloss_Reihe3_FA
    BT_AB_Gurtschloss_Reihe3_MI
    BT_AB_Gurtwarn_VB
    BT_AB_Gurtwarn_VF
    BT_AB_Heck_Crash
    BT_AB_Lampe
    BT_AB_MKB_Anforderung
    BT_AB_MKB_gueltig
    BT_AB_PAO_Leuchte_Anf
    BT_AB_RGS_Anst
    BT_AB_Rollover_Crash
    BT_AB_SB_Crash
    BT_AB_SF_Crash
    BT_AB_Sitzpos_Sens_BF
    BT_AB_Sitzpos_Sens_FA
    BT_AB_Stellgliedtest
    BT_AB_Systemfehler
    BT_AB_Texte_AKS
    BT_AB_VB_deaktiviert
    BT_AB_Versorgungsspannung
    BT_AB_Wickelklappung_Reihe2_BF
    BT_AB_Wickelklappung_Reihe2_FA
    BT_AB_Wickelklappung_Reihe2_MI
    BT_Airbag_01_BZ
    BT_Airbag_01_CRC
    BT_Airbag_02_BZ
    BT_Airbag_02_CRC
    BT_ASM_Masterzeit_02
    BT_eCS_Gurtschloss_Status_Reihe2_BF
    BT_eCS_Gurtschloss_Status_Reihe2_FA
    BT_eCS_HW_defekt
    BT_eCS_SBS_Belegung_Reihe2_BF
    BT_eCS_SBS_Belegung_Reihe2_FA
    BT_eCS_Status
    BT_eCS_Stoerung
    BT_LoGeWa_Event_Kombiwarnung
    BT_SC_PAO_OFF_Anf
    BT_SC_PAO_ON_Anf
    BT_SC_PAO_Schriftzug_Anf
    BT_SignalVoid
package /Unit
  unit Unit_Unit_Secon: display-name=Unit_Secon, factor-si-to-unit=1.0, physical-dimension=PD_siSecond
package /PhysicalDimension
  physical dimension PD_siSecond: time-exp=1
package /TPConfig
  can tp config CanTPConfig_Airbag_SUBCANFD: communication-cluster=Airbag_SUBCANFD, can-tp-ecu=eCS
    8 x can tp address:
      TA_0x1C404206: tp-address=473973254
      TA_0x1C424206: tp-address=474104326
      TA_0x1C405206: tp-address=473977350
      TA_0x1C425206: tp-address=474108422
      TA_0x1C407206: tp-address=473985542
      TA_0x1C427206: tp-address=474116614
      TA_0x17FC4206: tp-address=402407942
      TA_0x17FE4206: tp-address=402539014
    4 x can tp channel, all with channel-mode=HALF-DUPLEX-MODE:
      TPC_Airbag_SUBCANFD_XIX_TPCHType_CANFD_Flash_DIA_XIX_0x1C404206_XIX_0x1C424206_XIX_Physical: channel-id=2060928652
      TPC_Airbag_SUBCANFD_XIX_TPCHType_CANFD_Diag_XIX_0x1C405206_XIX_0x1C425206_XIX_Physical: channel-id=1449258196
      TPC_Airbag_SUBCANFD_XIX_TPCHType_CANFD_OBDC_SSN_Diagnose_XIX_0x1C407206_XIX_0x1C427206_XIX_Physical: channel-id=1803922309
      TPC_Airbag_SUBCANFD_XIX_TPCHType_CANHS_Flash_DIA_XIX_0x17FC4206_XIX_0x17FE4206_XIX_Physical: channel-id=1639721959
    can-tp-connection addressing-format=STANDARD, can-tp-channel=TPC_Airbag_SUBCANFD_XIX_TPCHType_CANFD_Diag_XIX_0x1C405206_XIX_0x1C425206_XIX_Physical, cancellation=true, data-pdu=Diag_eCS_Req_FD_XIX_Airbag_SUBCANFD, flow-control-pdu=Diag_eCS_Resp_FD_XIX_Airbag_SUBCANFD, max-block-size=15, padding-activation=true, receiver=TPN_eCS_XIX_Airbag_SUBCANFD_XIX_0x1C425206, ta-type=PHYSICAL, timeout-br=0.1, timeout-bs=1.0, timeout-cr=1.0, timeout-cs=0.2, tp-sdu=DCM_Airbag_SUBCANFD_XIX_TPCHType_CANFD_Diag_XIX_0x1C405206_XIX_0x1C425206_XIX_Physical, transmitter=TPN_Airbag_01_XIX_Airbag_SUBCANFD_XIX_0x1C405206:
      ident TPCN_Airbag_SUBCANFD_XIX_TPCHType_CANFD_Diag_XIX_0x1C405206_Airbag_01_XIX_0x1C425206_eCS_XIX_Physical
    can-tp-connection addressing-format=STANDARD, can-tp-channel=TPC_Airbag_SUBCANFD_XIX_TPCHType_CANFD_Diag_XIX_0x1C405206_XIX_0x1C425206_XIX_Physical, cancellation=true, data-pdu=Diag_eCS_Resp_FD_XIX_Airbag_SUBCANFD, flow-control-pdu=Diag_eCS_Req_FD_XIX_Airbag_SUBCANFD, max-block-size=15, padding-activation=true, receiver=TPN_Airbag_01_XIX_Airbag_SUBCANFD_XIX_0x1C405206, ta-type=PHYSICAL, timeout-br=0.1, timeout-bs=1.0, timeout-cr=1.0, timeout-cs=0.2, tp-sdu=DCM_Airbag_SUBCANFD_XIX_TPCHType_CANFD_Diag_XIX_0x1C425206_XIX_0x1C405206_XIX_Physical, transmitter=TPN_eCS_XIX_Airbag_SUBCANFD_XIX_0x1C425206:
      ident TPCN_Airbag_SUBCANFD_XIX_TPCHType_CANFD_Diag_XIX_0x1C425206_eCS_XIX_0x1C405206_Airbag_01_XIX_Physical
    can-tp-connection addressing-format=STANDARD, can-tp-channel=TPC_Airbag_SUBCANFD_XIX_TPCHType_CANFD_Flash_DIA_XIX_0x1C404206_XIX_0x1C424206_XIX_Physical, cancellation=true, data-pdu=DIA_eCS_Req_FD_XIX_Airbag_SUBCANFD, flow-control-pdu=DIA_eCS_Resp_FD_XIX_Airbag_SUBCANFD, max-block-size=15, padding-activation=true, receiver=TPN_eCS_XIX_Airbag_SUBCANFD_XIX_0x1C424206, ta-type=PHYSICAL, timeout-br=0.1, timeout-bs=1.0, timeout-cr=1.0, timeout-cs=0.2, tp-sdu=DCM_Airbag_SUBCANFD_XIX_TPCHType_CANFD_Flash_DIA_XIX_0x1C404206_XIX_0x1C424206_XIX_Physical, transmitter=TPN_Airbag_01_XIX_Airbag_SUBCANFD_XIX_0x1C404206:
      ident TPCN_Airbag_SUBCANFD_XIX_TPCHType_CANFD_Flash_DIA_XIX_0x1C404206_Airbag_01_XIX_0x1C424206_eCS_XIX_Physical
    can-tp-connection addressing-format=STANDARD, can-tp-channel=TPC_Airbag_SUBCANFD_XIX_TPCHType_CANFD_Flash_DIA_XIX_0x1C404206_XIX_0x1C424206_XIX_Physical, cancellation=true, data-pdu=DIA_eCS_Resp_FD_XIX_Airbag_SUBCANFD, flow-control-pdu=DIA_eCS_Req_FD_XIX_Airbag_SUBCANFD, max-block-size=15, padding-activation=true, receiver=TPN_Airbag_01_XIX_Airbag_SUBCANFD_XIX_0x1C404206, ta-type=PHYSICAL, timeout-br=0.1, timeout-bs=1.0, timeout-cr=1.0, timeout-cs=0.2, tp-sdu=DCM_Airbag_SUBCANFD_XIX_TPCHType_CANFD_Flash_DIA_XIX_0x1C424206_XIX_0x1C404206_XIX_Physical, transmitter=TPN_eCS_XIX_Airbag_SUBCANFD_XIX_0x1C424206:
      ident TPCN_Airbag_SUBCANFD_XIX_TPCHType_CANFD_Flash_DIA_XIX_0x1C424206_eCS_XIX_0x1C404206_Airbag_01_XIX_Physical
    can-tp-connection addressing-format=STANDARD, can-tp-channel=TPC_Airbag_SUBCANFD_XIX_TPCHType_CANFD_OBDC_SSN_Diagnose_XIX_0x1C407206_XIX_0x1C427206_XIX_Physical, cancellation=true, data-pdu=OBDC_SSN_eCS_Req_FD_XIX_Airbag_SUBCANFD, flow-control-pdu=OBDC_SSN_eCS_Resp_FD_XIX_Airbag_SUBCANFD, max-block-size=15, padding-activation=true, receiver=TPN_eCS_XIX_Airbag_SUBCANFD_XIX_0x1C427206, ta-type=PHYSICAL, timeout-br=0.1, timeout-bs=1.0, timeout-cr=1.0, timeout-cs=0.2, tp-sdu=DCM_Airbag_SUBCANFD_XIX_TPCHType_CANFD_OBDC_SSN_Diagnose_XIX_0x1C407206_XIX_0x1C427206_XIX_Physical, transmitter=TPN_Airbag_01_XIX_Airbag_SUBCANFD_XIX_0x1C407206:
      ident TPCN_Airbag_SUBCANFD_XIX_TPCHType_CANFD_OBDC_SSN_Diagnose_XIX_0x1C407206_Airbag_01_XIX_0x1C427206_eCS_XIX_Physical
    can-tp-connection addressing-format=STANDARD, can-tp-channel=TPC_Airbag_SUBCANFD_XIX_TPCHType_CANFD_OBDC_SSN_Diagnose_XIX_0x1C407206_XIX_0x1C427206_XIX_Physical, cancellation=true, data-pdu=OBDC_SSN_eCS_Resp_FD_XIX_Airbag_SUBCANFD, flow-control-pdu=OBDC_SSN_eCS_Req_FD_XIX_Airbag_SUBCANFD, max-block-size=15, padding-activation=true, receiver=TPN_Airbag_01_XIX_Airbag_SUBCANFD_XIX_0x1C407206, ta-type=PHYSICAL, timeout-br=0.1, timeout-bs=1.0, timeout-cr=1.0, timeout-cs=0.2, tp-sdu=DCM_Airbag_SUBCANFD_XIX_TPCHType_CANFD_OBDC_SSN_Diagnose_XIX_0x1C427206_XIX_0x1C407206_XIX_Physical, transmitter=TPN_eCS_XIX_Airbag_SUBCANFD_XIX_0x1C427206:
      ident TPCN_Airbag_SUBCANFD_XIX_TPCHType_CANFD_OBDC_SSN_Diagnose_XIX_0x1C427206_eCS_XIX_0x1C407206_Airbag_01_XIX_Physical
    can-tp-connection addressing-format=STANDARD, can-tp-channel=TPC_Airbag_SUBCANFD_XIX_TPCHType_CANHS_Flash_DIA_XIX_0x17FC4206_XIX_0x17FE4206_XIX_Physical, cancellation=true, data-pdu=DIA_eCS_Req_XIX_Airbag_SUBCANFD, flow-control-pdu=DIA_eCS_Resp_XIX_Airbag_SUBCANFD, max-block-size=15, padding-activation=true, receiver=TPN_eCS_XIX_Airbag_SUBCANFD_XIX_0x17FE4206, ta-type=PHYSICAL, timeout-br=0.1, timeout-bs=1.0, timeout-cr=1.0, timeout-cs=0.2, tp-sdu=DCM_Airbag_SUBCANFD_XIX_TPCHType_CANHS_Flash_DIA_XIX_0x17FC4206_XIX_0x17FE4206_XIX_Physical, transmitter=TPN_Airbag_01_XIX_Airbag_SUBCANFD_XIX_0x17FC4206:
      ident TPCN_Airbag_SUBCANFD_XIX_TPCHType_CANHS_Flash_DIA_XIX_0x17FC4206_Airbag_01_XIX_0x17FE4206_eCS_XIX_Physical
    can-tp-connection addressing-format=STANDARD, can-tp-channel=TPC_Airbag_SUBCANFD_XIX_TPCHType_CANHS_Flash_DIA_XIX_0x17FC4206_XIX_0x17FE4206_XIX_Physical, cancellation=true, data-pdu=DIA_eCS_Resp_XIX_Airbag_SUBCANFD, flow-control-pdu=DIA_eCS_Req_XIX_Airbag_SUBCANFD, max-block-size=15, padding-activation=true, receiver=TPN_Airbag_01_XIX_Airbag_SUBCANFD_XIX_0x17FC4206, ta-type=PHYSICAL, timeout-br=0.1, timeout-bs=1.0, timeout-cr=1.0, timeout-cs=0.2, tp-sdu=DCM_Airbag_SUBCANFD_XIX_TPCHType_CANHS_Flash_DIA_XIX_0x17FE4206_XIX_0x17FC4206_XIX_Physical, transmitter=TPN_eCS_XIX_Airbag_SUBCANFD_XIX_0x17FE4206:
      ident TPCN_Airbag_SUBCANFD_XIX_TPCHType_CANHS_Flash_DIA_XIX_0x17FE4206_eCS_XIX_0x17FC4206_Airbag_01_XIX_Physical
    8 x can tp node, all with max-fc-wait=15, st-min=0.005, timeout-ar=1.0, timeout-as=1.0:
      TPN_Airbag_01_XIX_Airbag_SUBCANFD_XIX_0x17FC4206: tp-address=TA_0x17FC4206
      TPN_Airbag_01_XIX_Airbag_SUBCANFD_XIX_0x1C404206: tp-address=TA_0x1C404206
      TPN_Airbag_01_XIX_Airbag_SUBCANFD_XIX_0x1C405206: tp-address=TA_0x1C405206
      TPN_Airbag_01_XIX_Airbag_SUBCANFD_XIX_0x1C407206: tp-address=TA_0x1C407206
      TPN_eCS_XIX_Airbag_SUBCANFD_XIX_0x17FE4206: connector=CN_Airbag_SUBCANFD, tp-address=TA_0x17FE4206
      TPN_eCS_XIX_Airbag_SUBCANFD_XIX_0x1C424206: connector=CN_Airbag_SUBCANFD, tp-address=TA_0x1C424206
      TPN_eCS_XIX_Airbag_SUBCANFD_XIX_0x1C425206: connector=CN_Airbag_SUBCANFD, tp-address=TA_0x1C425206
      TPN_eCS_XIX_Airbag_SUBCANFD_XIX_0x1C427206: connector=CN_Airbag_SUBCANFD, tp-address=TA_0x1C427206
package /DiagnosticServices
  4 x diagnostic connection:
    DC_eCS_XIX_TPCHType_CANHS_Flash_DIA: physical-request=TPCN_Airbag_SUBCANFD_XIX_TPCHType_CANHS_Flash_DIA_XIX_0x17FC4206_Airbag_01_XIX_0x17FE4206_eCS_XIX_Physical, response=TPCN_Airbag_SUBCANFD_XIX_TPCHType_CANHS_Flash_DIA_XIX_0x17FE4206_eCS_XIX_0x17FC4206_Airbag_01_XIX_Physical
    DC_eCS_XIX_TPCHType_CANFD_Flash_DIA: physical-request=TPCN_Airbag_SUBCANFD_XIX_TPCHType_CANFD_Flash_DIA_XIX_0x1C404206_Airbag_01_XIX_0x1C424206_eCS_XIX_Physical, response=TPCN_Airbag_SUBCANFD_XIX_TPCHType_CANFD_Flash_DIA_XIX_0x1C424206_eCS_XIX_0x1C404206_Airbag_01_XIX_Physical
    DC_eCS_XIX_TPCHType_CANFD_OBDC_SSN_Diagnose: physical-request=TPCN_Airbag_SUBCANFD_XIX_TPCHType_CANFD_OBDC_SSN_Diagnose_XIX_0x1C407206_Airbag_01_XIX_0x1C427206_eCS_XIX_Physical, response=TPCN_Airbag_SUBCANFD_XIX_TPCHType_CANFD_OBDC_SSN_Diagnose_XIX_0x1C427206_eCS_XIX_0x1C407206_Airbag_01_XIX_Physical
    DC_eCS_XIX_TPCHType_CANFD_Diag: physical-request=TPCN_Airbag_SUBCANFD_XIX_TPCHType_CANFD_Diag_XIX_0x1C405206_Airbag_01_XIX_0x1C425206_eCS_XIX_Physical, response=TPCN_Airbag_SUBCANFD_XIX_TPCHType_CANFD_Diag_XIX_0x1C425206_eCS_XIX_0x1C405206_Airbag_01_XIX_Physical
  diagnostic service table DST_eCS: ecu-instance=eCS
    diagnostic-connections:
      DC_eCS_XIX_TPCHType_CANFD_Diag
      DC_eCS_XIX_TPCHType_CANFD_Flash_DIA
      DC_eCS_XIX_TPCHType_CANFD_OBDC_SSN_Diagnose
      DC_eCS_XIX_TPCHType_CANHS_Flash_DIA
package /Interfaces
  20 x sender receiver interface:
    IF_AB_Crash_Int
      data DE_AB_Crash_Int: type=uint8
    IF_AB_Gurtschloss_Reihe3_BF
      data DE_AB_Gurtschloss_Reihe3_BF: type=uint8
    IF_AB_Gurtschloss_FA
      data DE_AB_Gurtschloss_FA: type=uint8
    IF_AB_Gurtschloss_Reihe2_BF
      data DE_AB_Gurtschloss_Reihe2_BF: type=uint8
    IF_AB_Gurtschloss_Reihe2_FA
      data DE_AB_Gurtschloss_Reihe2_FA: type=uint8
    IF_AB_Gurtschloss_BF
      data DE_AB_Gurtschloss_BF: type=uint8
    IF_AB_Gurtschloss_Reihe3_FA
      data DE_AB_Gurtschloss_Reihe3_FA: type=uint8
    IF_AB_eCS_Aktuatortest_FA
      data DE_AB_eCS_Aktuatortest_FA: type=uint8
    IF_eCS_HW_defekt
      data DE_eCS_HW_defekt: type=boolean
    IF_eCS_Stoerung
      data DE_eCS_Stoerung: type=boolean
    IF_eCS_Gurtschloss_Status_Reihe2_BF
      data DE_eCS_Gurtschloss_Status_Reihe2_BF: type=uint8
    IF_eCS_SBS_Belegung_Reihe2_FA
      data DE_eCS_SBS_Belegung_Reihe2_FA: type=uint8
    IF_eCS_SBS_Belegung_Reihe2_BF
      data DE_eCS_SBS_Belegung_Reihe2_BF: type=uint8
    IF_AB_eCS_Aktuatortest_Reihe2_BF
      data DE_AB_eCS_Aktuatortest_Reihe2_BF: type=uint8
    IF_AB_eCS_Aktuatortest_Reihe3_FA
      data DE_AB_eCS_Aktuatortest_Reihe3_FA: type=uint8
    IF_eCS_Gurtschloss_Status_Reihe2_FA
      data DE_eCS_Gurtschloss_Status_Reihe2_FA: type=uint8
    IF_AB_eCS_Aktuatortest_Reihe3_BF
      data DE_AB_eCS_Aktuatortest_Reihe3_BF: type=uint8
    IF_eCS_Status
      data DE_eCS_Status: type=uint8
    IF_AB_eCS_Aktuatortest_BF
      data DE_AB_eCS_Aktuatortest_BF: type=uint8
    IF_AB_eCS_Aktuatortest_Reihe2_FA
      data DE_AB_eCS_Aktuatortest_Reihe2_FA: type=uint8
package /ComponentTypes
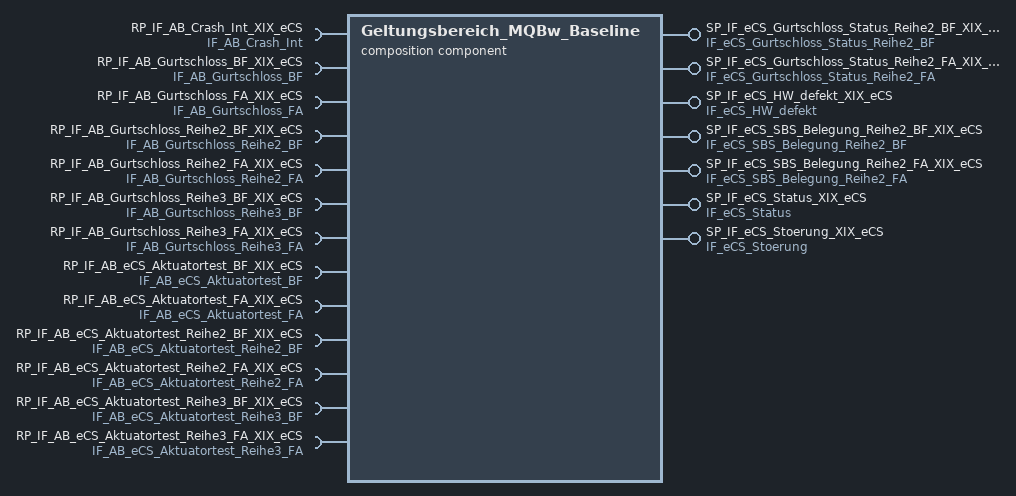
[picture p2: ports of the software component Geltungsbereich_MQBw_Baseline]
  composition sw component type Geltungsbereich_MQBw_Baseline
    7 x provide port:
      SP_IF_eCS_Gurtschloss_Status_Reihe2_BF_XIX_eCS: provided-interface=IF_eCS_Gurtschloss_Status_Reihe2_BF
      SP_IF_eCS_Gurtschloss_Status_Reihe2_FA_XIX_eCS: provided-interface=IF_eCS_Gurtschloss_Status_Reihe2_FA
      SP_IF_eCS_HW_defekt_XIX_eCS: provided-interface=IF_eCS_HW_defekt
      SP_IF_eCS_SBS_Belegung_Reihe2_BF_XIX_eCS: provided-interface=IF_eCS_SBS_Belegung_Reihe2_BF
      SP_IF_eCS_SBS_Belegung_Reihe2_FA_XIX_eCS: provided-interface=IF_eCS_SBS_Belegung_Reihe2_FA
      SP_IF_eCS_Status_XIX_eCS: provided-interface=IF_eCS_Status
      SP_IF_eCS_Stoerung_XIX_eCS: provided-interface=IF_eCS_Stoerung
    13 x require port:
      RP_IF_AB_Crash_Int_XIX_eCS: required-interface=IF_AB_Crash_Int
      RP_IF_AB_Gurtschloss_BF_XIX_eCS: required-interface=IF_AB_Gurtschloss_BF
      RP_IF_AB_Gurtschloss_FA_XIX_eCS: required-interface=IF_AB_Gurtschloss_FA
      RP_IF_AB_Gurtschloss_Reihe2_BF_XIX_eCS: required-interface=IF_AB_Gurtschloss_Reihe2_BF
      RP_IF_AB_Gurtschloss_Reihe2_FA_XIX_eCS: required-interface=IF_AB_Gurtschloss_Reihe2_FA
      RP_IF_AB_Gurtschloss_Reihe3_BF_XIX_eCS: required-interface=IF_AB_Gurtschloss_Reihe3_BF
      RP_IF_AB_Gurtschloss_Reihe3_FA_XIX_eCS: required-interface=IF_AB_Gurtschloss_Reihe3_FA
      RP_IF_AB_eCS_Aktuatortest_BF_XIX_eCS: required-interface=IF_AB_eCS_Aktuatortest_BF
      RP_IF_AB_eCS_Aktuatortest_FA_XIX_eCS: required-interface=IF_AB_eCS_Aktuatortest_FA
      RP_IF_AB_eCS_Aktuatortest_Reihe2_BF_XIX_eCS: required-interface=IF_AB_eCS_Aktuatortest_Reihe2_BF
      RP_IF_AB_eCS_Aktuatortest_Reihe2_FA_XIX_eCS: required-interface=IF_AB_eCS_Aktuatortest_Reihe2_FA
      RP_IF_AB_eCS_Aktuatortest_Reihe3_BF_XIX_eCS: required-interface=IF_AB_eCS_Aktuatortest_Reihe3_BF
      RP_IF_AB_eCS_Aktuatortest_Reihe3_FA_XIX_eCS: required-interface=IF_AB_eCS_Aktuatortest_Reihe3_FA
    component Grundumfang_XIX_eCS: type=Grundumfang_XIX_eCS
    delegate Grundumfang_XIX_eCS.RP_IF_AB_Crash_Int_XIX_Grundumfang_XIX_eCS <-> outer port RP_IF_AB_Crash_Int_XIX_eCS
    delegate Grundumfang_XIX_eCS.RP_IF_AB_Gurtschloss_BF_XIX_Grundumfang_XIX_eCS <-> outer port RP_IF_AB_Gurtschloss_BF_XIX_eCS
    delegate Grundumfang_XIX_eCS.RP_IF_AB_Gurtschloss_FA_XIX_Grundumfang_XIX_eCS <-> outer port RP_IF_AB_Gurtschloss_FA_XIX_eCS
    delegate Grundumfang_XIX_eCS.RP_IF_AB_Gurtschloss_Reihe2_BF_XIX_Grundumfang_XIX_eCS <-> outer port RP_IF_AB_Gurtschloss_Reihe2_BF_XIX_eCS
    delegate Grundumfang_XIX_eCS.RP_IF_AB_Gurtschloss_Reihe2_FA_XIX_Grundumfang_XIX_eCS <-> outer port RP_IF_AB_Gurtschloss_Reihe2_FA_XIX_eCS
    delegate Grundumfang_XIX_eCS.RP_IF_AB_Gurtschloss_Reihe3_BF_XIX_Grundumfang_XIX_eCS <-> outer port RP_IF_AB_Gurtschloss_Reihe3_BF_XIX_eCS
    delegate Grundumfang_XIX_eCS.RP_IF_AB_Gurtschloss_Reihe3_FA_XIX_Grundumfang_XIX_eCS <-> outer port RP_IF_AB_Gurtschloss_Reihe3_FA_XIX_eCS
    delegate Grundumfang_XIX_eCS.RP_IF_AB_eCS_Aktuatortest_BF_XIX_Grundumfang_XIX_eCS <-> outer port RP_IF_AB_eCS_Aktuatortest_BF_XIX_eCS
    delegate Grundumfang_XIX_eCS.RP_IF_AB_eCS_Aktuatortest_FA_XIX_Grundumfang_XIX_eCS <-> outer port RP_IF_AB_eCS_Aktuatortest_FA_XIX_eCS
    delegate Grundumfang_XIX_eCS.RP_IF_AB_eCS_Aktuatortest_Reihe2_BF_XIX_Grundumfang_XIX_eCS <-> outer port RP_IF_AB_eCS_Aktuatortest_Reihe2_BF_XIX_eCS
    delegate Grundumfang_XIX_eCS.RP_IF_AB_eCS_Aktuatortest_Reihe2_FA_XIX_Grundumfang_XIX_eCS <-> outer port RP_IF_AB_eCS_Aktuatortest_Reihe2_FA_XIX_eCS
    delegate Grundumfang_XIX_eCS.RP_IF_AB_eCS_Aktuatortest_Reihe3_BF_XIX_Grundumfang_XIX_eCS <-> outer port RP_IF_AB_eCS_Aktuatortest_Reihe3_BF_XIX_eCS
    delegate Grundumfang_XIX_eCS.RP_IF_AB_eCS_Aktuatortest_Reihe3_FA_XIX_Grundumfang_XIX_eCS <-> outer port RP_IF_AB_eCS_Aktuatortest_Reihe3_FA_XIX_eCS
    delegate Grundumfang_XIX_eCS.SP_IF_eCS_Gurtschloss_Status_Reihe2_BF_XIX_Grundumfang_XIX_eCS <-> outer port SP_IF_eCS_Gurtschloss_Status_Reihe2_BF_XIX_eCS
    delegate Grundumfang_XIX_eCS.SP_IF_eCS_Gurtschloss_Status_Reihe2_FA_XIX_Grundumfang_XIX_eCS <-> outer port SP_IF_eCS_Gurtschloss_Status_Reihe2_FA_XIX_eCS
    delegate Grundumfang_XIX_eCS.SP_IF_eCS_HW_defekt_XIX_Grundumfang_XIX_eCS <-> outer port SP_IF_eCS_HW_defekt_XIX_eCS
    delegate Grundumfang_XIX_eCS.SP_IF_eCS_SBS_Belegung_Reihe2_BF_XIX_Grundumfang_XIX_eCS <-> outer port SP_IF_eCS_SBS_Belegung_Reihe2_BF_XIX_eCS
    delegate Grundumfang_XIX_eCS.SP_IF_eCS_SBS_Belegung_Reihe2_FA_XIX_Grundumfang_XIX_eCS <-> outer port SP_IF_eCS_SBS_Belegung_Reihe2_FA_XIX_eCS
    delegate Grundumfang_XIX_eCS.SP_IF_eCS_Status_XIX_Grundumfang_XIX_eCS <-> outer port SP_IF_eCS_Status_XIX_eCS
    delegate Grundumfang_XIX_eCS.SP_IF_eCS_Stoerung_XIX_Grundumfang_XIX_eCS <-> outer port SP_IF_eCS_Stoerung_XIX_eCS
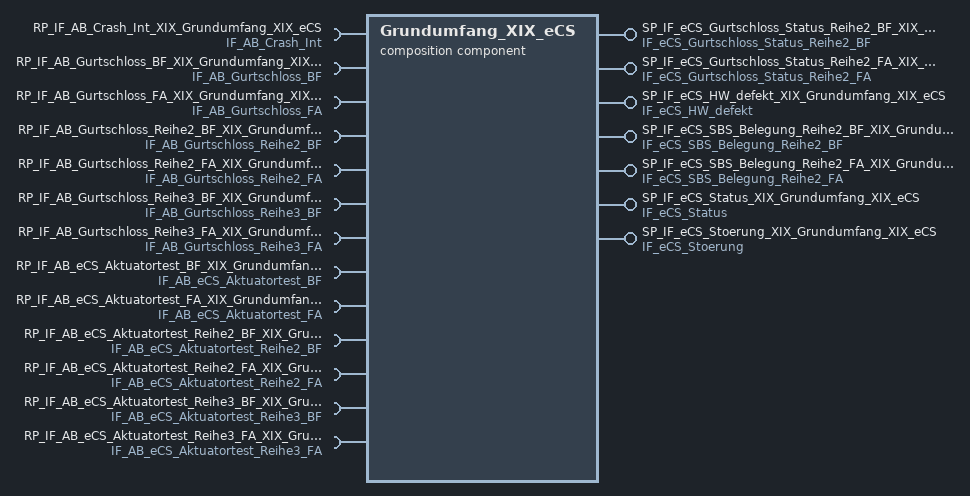
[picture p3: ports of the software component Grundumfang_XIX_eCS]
  composition sw component type Grundumfang_XIX_eCS
    7 x provide port:
      SP_IF_eCS_Gurtschloss_Status_Reihe2_BF_XIX_Grundumfang_XIX_eCS: provided-interface=IF_eCS_Gurtschloss_Status_Reihe2_BF
      SP_IF_eCS_Gurtschloss_Status_Reihe2_FA_XIX_Grundumfang_XIX_eCS: provided-interface=IF_eCS_Gurtschloss_Status_Reihe2_FA
      SP_IF_eCS_HW_defekt_XIX_Grundumfang_XIX_eCS: provided-interface=IF_eCS_HW_defekt
      SP_IF_eCS_SBS_Belegung_Reihe2_BF_XIX_Grundumfang_XIX_eCS: provided-interface=IF_eCS_SBS_Belegung_Reihe2_BF
      SP_IF_eCS_SBS_Belegung_Reihe2_FA_XIX_Grundumfang_XIX_eCS: provided-interface=IF_eCS_SBS_Belegung_Reihe2_FA
      SP_IF_eCS_Status_XIX_Grundumfang_XIX_eCS: provided-interface=IF_eCS_Status
      SP_IF_eCS_Stoerung_XIX_Grundumfang_XIX_eCS: provided-interface=IF_eCS_Stoerung
    13 x require port:
      RP_IF_AB_Crash_Int_XIX_Grundumfang_XIX_eCS: required-interface=IF_AB_Crash_Int
      RP_IF_AB_Gurtschloss_BF_XIX_Grundumfang_XIX_eCS: required-interface=IF_AB_Gurtschloss_BF
      RP_IF_AB_Gurtschloss_FA_XIX_Grundumfang_XIX_eCS: required-interface=IF_AB_Gurtschloss_FA
      RP_IF_AB_Gurtschloss_Reihe2_BF_XIX_Grundumfang_XIX_eCS: required-interface=IF_AB_Gurtschloss_Reihe2_BF
      RP_IF_AB_Gurtschloss_Reihe2_FA_XIX_Grundumfang_XIX_eCS: required-interface=IF_AB_Gurtschloss_Reihe2_FA
      RP_IF_AB_Gurtschloss_Reihe3_BF_XIX_Grundumfang_XIX_eCS: required-interface=IF_AB_Gurtschloss_Reihe3_BF
      RP_IF_AB_Gurtschloss_Reihe3_FA_XIX_Grundumfang_XIX_eCS: required-interface=IF_AB_Gurtschloss_Reihe3_FA
      RP_IF_AB_eCS_Aktuatortest_BF_XIX_Grundumfang_XIX_eCS: required-interface=IF_AB_eCS_Aktuatortest_BF
      RP_IF_AB_eCS_Aktuatortest_FA_XIX_Grundumfang_XIX_eCS: required-interface=IF_AB_eCS_Aktuatortest_FA
      RP_IF_AB_eCS_Aktuatortest_Reihe2_BF_XIX_Grundumfang_XIX_eCS: required-interface=IF_AB_eCS_Aktuatortest_Reihe2_BF
      RP_IF_AB_eCS_Aktuatortest_Reihe2_FA_XIX_Grundumfang_XIX_eCS: required-interface=IF_AB_eCS_Aktuatortest_Reihe2_FA
      RP_IF_AB_eCS_Aktuatortest_Reihe3_BF_XIX_Grundumfang_XIX_eCS: required-interface=IF_AB_eCS_Aktuatortest_Reihe3_BF
      RP_IF_AB_eCS_Aktuatortest_Reihe3_FA_XIX_Grundumfang_XIX_eCS: required-interface=IF_AB_eCS_Aktuatortest_Reihe3_FA
package /AUTOSAR_PlatformTypes/DataConstraints
  range DataConstr_sint8: phys -128..127, raw -128..127
  range DataConstr_sint16: phys -32768..32767, raw -32768..32767
  range DataConstr_sint32: phys -2147483648..2147483647, raw -2147483648..2147483647
  range DataConstr_sint64: phys -9223372036854775808..9223372036854775807, raw -9223372036854775808..9223372036854775807
  range DataConstr_uint8: phys 0..255, raw 0..255
  range DataConstr_uint16: phys 0..65535, raw 0..65535
  range DataConstr_uint32: phys 0..4294967295, raw 0..4294967295
  range DataConstr_uint64: phys 0..18446744073709551615, raw 0..18446744073709551615
  range DataConstr_boolean: raw 0..1
package /AUTOSAR_PlatformTypes/CompuMethods
  compu method CompuMethod_boolean: 0=false (CompuMethod_boolean_false), 1=true (CompuMethod_boolean_true)
